AUTOSAR XML (schema 4-2-1)
package /RootP_ASWC_M137
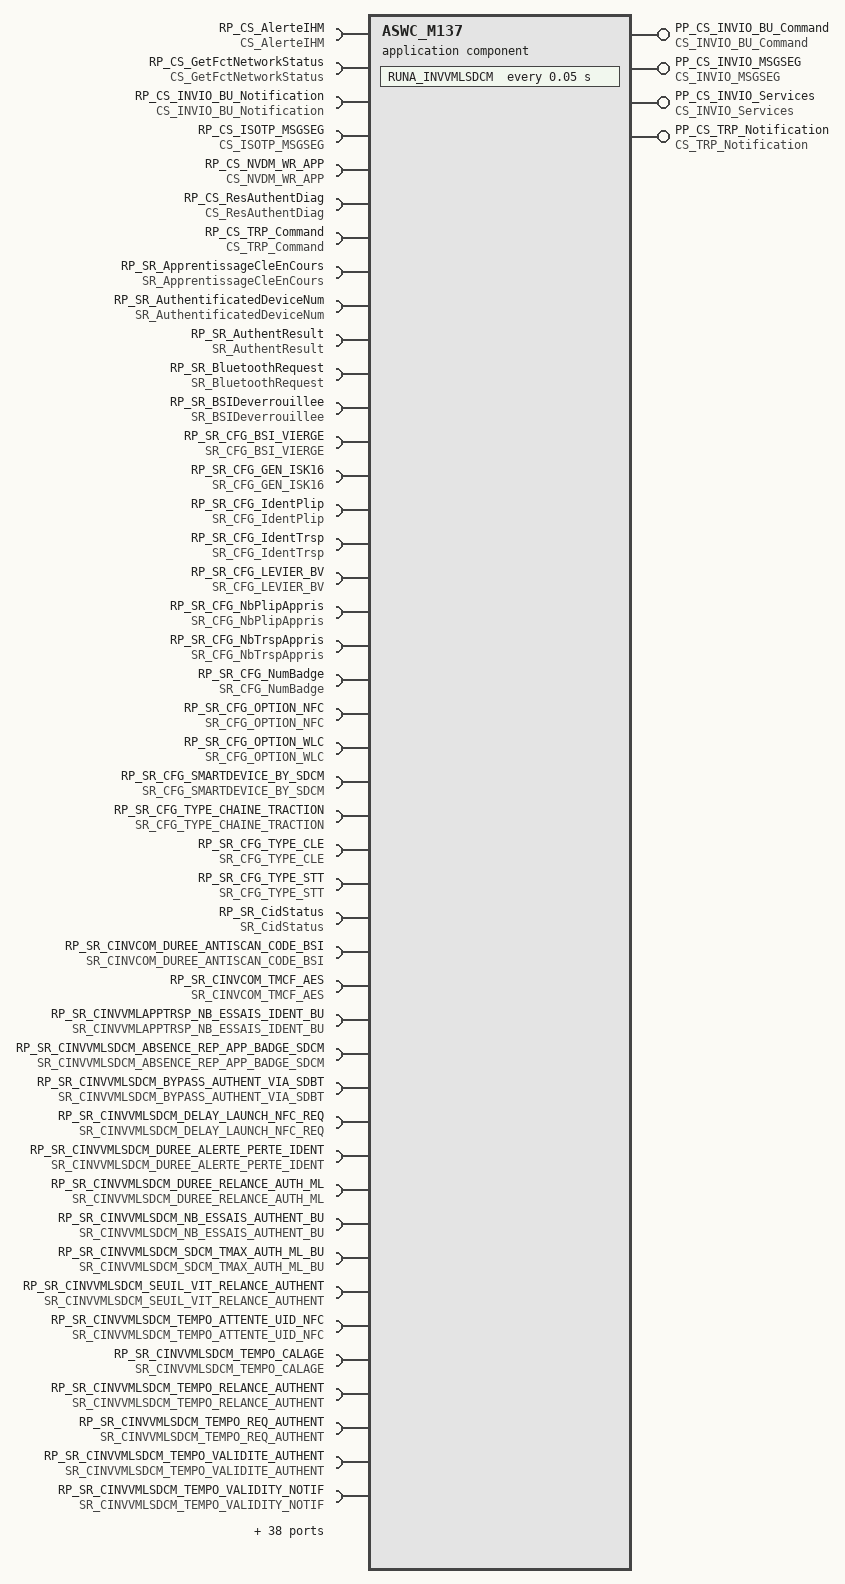
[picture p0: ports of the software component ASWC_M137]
  application sw component type ASWC_M137
    4 x provide port:
      PP_CS_INVIO_BU_Command: provided-interface=CS_INVIO_BU_Command
        provided-com-specs:
          operation=Invio_AuthentRequest, queue-length=1
          operation=Invio_CfgReadRequest, queue-length=1
          operation=Invio_CfgWriteRequest, queue-length=1
          operation=Invio_IdentRequest, queue-length=1
          operation=Invio_ReadRequest, queue-length=1
          operation=Invio_WriteRequest, queue-length=1
      PP_CS_INVIO_MSGSEG: server-com-spec{operation=Invio_ReceiveSegMsg, queue-length=1}, provided-interface=CS_INVIO_MSGSEG
      PP_CS_INVIO_Services: provided-interface=CS_INVIO_Services
        provided-com-specs:
          operation=Invio_CalculerDataAuthent, queue-length=1
          operation=Invio_CalculerRSK, queue-length=1
          operation=Invio_FinAppr, queue-length=1
          operation=Invio_GetCIDAndStatus, queue-length=1
          operation=Invio_LocalisationMLEnCours, queue-length=1
      PP_CS_TRP_Notification: provided-interface=CS_TRP_Notification
        provided-com-specs:
          operation=Authent_Result, queue-length=1
          operation=Cfg_Read_Result, queue-length=1
          operation=Cfg_Write_Result, queue-length=1
          operation=Error, queue-length=1
          operation=Ident_Result, queue-length=1
          operation=Read_Result, queue-length=1
          operation=Write_Result, queue-length=1
    33 x provide/require port:
      PRP_SR_AnimationPushDem: provided-required-interface=SR_AnimationPushDem
        required-com-specs:
          data-element=DmdPoumonagePushDem, enable-update=0, handle-data-status=1, handle-never-received=0, init-value=CONST_DmdPoumonagePushDem_t_cDmdPoumonagePushDem_cDmdPoumonagePushDem_Aucun:0
          data-element=DmdRetroPushDem, enable-update=0, handle-data-status=1, handle-never-received=0, init-value=CONST_DmdRetroPushDem_t_cPushDem_cPushDem_Eteint:0
      PRP_SR_AppuiPushTraite: nonqueued-receiver-com-spec{data-element=AppuiPushTraite, enable-update=0, handle-data-status=1, handle-never-received=0, init-value=CONST_tLOG_0:0}, provided-required-interface=SR_AppuiPushTraite
      PRP_SR_AuthentBUDemandee: nonqueued-receiver-com-spec{data-element=AuthentBUDemandee, enable-update=0, handle-data-status=1, handle-never-received=0, init-value=CONST_tLOG_0:0}, provided-required-interface=SR_AuthentBUDemandee
      PRP_SR_AuthentificationBU: nonqueued-receiver-com-spec{data-element=AuthentificationBU, enable-update=0, handle-data-status=1, handle-never-received=0, init-value=CONST_tLOG_0:0}, provided-required-interface=SR_AuthentificationBU
      PRP_SR_AuthentificationBUMux: nonqueued-receiver-com-spec{data-element=AuthentificationBUMux, enable-update=0, handle-data-status=1, handle-never-received=0, init-value=CONST_tLOG_0:0}, provided-required-interface=SR_AuthentificationBUMux
      PRP_SR_AuthentificationML: nonqueued-receiver-com-spec{data-element=AuthentificationML, enable-update=0, handle-data-status=1, handle-never-received=0, init-value=CONST_tLOG_0:0}, provided-required-interface=SR_AuthentificationML
      PRP_SR_AuthentificationMLnonSDF: nonqueued-receiver-com-spec{data-element=AuthentificationMLnonSDF, enable-update=0, handle-data-status=1, handle-never-received=0, init-value=CONST_tLOG_0:0}, provided-required-interface=SR_AuthentificationMLnonSDF
      PRP_SR_AuthentMLDemandee: nonqueued-receiver-com-spec{data-element=AuthentMLDemandee, enable-update=0, handle-data-status=1, handle-never-received=0, init-value=CONST_tLOG_0:0}, provided-required-interface=SR_AuthentMLDemandee
      PRP_SR_DmdAffIHMAuthent: nonqueued-receiver-com-spec{data-element=DmdAffIHMAuthent, enable-update=0, handle-data-status=1, handle-never-received=0, init-value=CONST_tLOG_0:0}, provided-required-interface=SR_DmdAffIHMAuthent
      PRP_SR_DmdAuthentBU: nonqueued-receiver-com-spec{data-element=DmdAuthentBU, enable-update=0, handle-data-status=1, handle-never-received=0, init-value=CONST_tQUARTET_0:0}, provided-required-interface=SR_DmdAuthentBU
      PRP_SR_DmdIdentBU: nonqueued-receiver-com-spec{data-element=DmdIdentBU, enable-update=0, handle-data-status=1, handle-never-received=0, init-value=CONST_tQUARTET_0:0}, provided-required-interface=SR_DmdIdentBU
      PRP_SR_EtatLocalisationML: nonqueued-receiver-com-spec{data-element=EtatLocalisationML, enable-update=0, handle-data-status=1, handle-never-received=0, init-value=CONST_EtatLocalisationML_t_Localis_cNonLocalise:0}, provided-required-interface=SR_EtatLocalisationML
      PRP_SR_HfResultatAuthentML: nonqueued-receiver-com-spec{data-element=ToggleAuthentML, enable-update=0, handle-data-status=1, handle-never-received=0, init-value=CONST_tLOG_0:0}, provided-required-interface=SR_HfResultatAuthentML
      PRP_SR_IdentBUDemandee: nonqueued-receiver-com-spec{data-element=IdentBUDemandee, enable-update=0, handle-data-status=1, handle-never-received=0, init-value=CONST_tLOG_0:0}, provided-required-interface=SR_IdentBUDemandee
      PRP_SR_IdentTrspBU: nonqueued-receiver-com-spec{data-element=IdentTrspBU, enable-update=0, handle-data-status=1, handle-never-received=0, init-value=CONST_tDWORD_0:0}, provided-required-interface=SR_IdentTrspBU
      PRP_SR_LastIdUsedToStart: provided-required-interface=SR_LastIdUsedToStart
        required-com-specs:
          data-element=LastNumIdUsedToStart, enable-update=0, handle-data-status=1, handle-never-received=0, init-value=CONST_tBYTE_0:0
          data-element=LastTypeIdUsedToStart, enable-update=0, handle-data-status=1, handle-never-received=0, init-value=CONST_t_cLastTypeId_0:0
      PRP_SR_NbNFCUidAppris: nonqueued-receiver-com-spec{data-element=NbNFCUidAppris, enable-update=0, handle-data-status=1, handle-never-received=0, init-value=CONST_tBYTE_0:0}, provided-required-interface=SR_NbNFCUidAppris
      PRP_SR_NFCUidLearningEcuState: nonqueued-receiver-com-spec{data-element=NFCUidLearningEcuState, enable-update=0, handle-data-status=1, handle-never-received=0, init-value=CONST_tLOG_0:0}, provided-required-interface=SR_NFCUidLearningEcuState
      PRP_SR_NoIMLAuthentOnStartRequest: nonqueued-receiver-com-spec{data-element=NoIMLAuthentOnStartRequest, enable-update=0, handle-data-status=1, handle-never-received=0, init-value=CONST_tLOG_0:0}, provided-required-interface=SR_NoIMLAuthentOnStartRequest
      PRP_SR_PresenceClefAppriseBU: nonqueued-receiver-com-spec{data-element=PresenceClefAppriseBU, enable-update=0, handle-data-status=1, handle-never-received=0, init-value=CONST_tLOG_0:0}, provided-required-interface=SR_PresenceClefAppriseBU
      PRP_SR_ReqAuthentBTSD: nonqueued-receiver-com-spec{data-element=ReqAuthentBTSD, enable-update=0, handle-data-status=1, handle-never-received=0, init-value=CONST_t_cReqAuthent_0:0}, provided-required-interface=SR_ReqAuthentBTSD
      PRP_SR_ReqAuthentCID: nonqueued-receiver-com-spec{data-element=ReqAuthentCID, enable-update=0, handle-data-status=1, handle-never-received=0, init-value=CONST_t_cReqAuthent_0:0}, provided-required-interface=SR_ReqAuthentCID
      PRP_SR_ReqAuthentNFCCard: nonqueued-receiver-com-spec{data-element=ReqAuthentNFCCard, enable-update=0, handle-data-status=1, handle-never-received=0, init-value=CONST_t_cReqAuthent_0:0}, provided-required-interface=SR_ReqAuthentNFCCard
      PRP_SR_ReqAuthentNFCSD: nonqueued-receiver-com-spec{data-element=ReqAuthentNFCSD, enable-update=0, handle-data-status=1, handle-never-received=0, init-value=CONST_t_cReqAuthent_0:0}, provided-required-interface=SR_ReqAuthentNFCSD
      PRP_SR_ReqLearnUIDTableBSI: nonqueued-receiver-com-spec{data-element=ReqLearnUIDTableToBSI, enable-update=0, handle-data-status=1, handle-never-received=0, init-value=CONST_tLOG_0:0}, provided-required-interface=SR_ReqLearnUIDTableBSI
      PRP_SR_SDCMBlacklistingRq: nonqueued-receiver-com-spec{data-element=SDCMBlacklistingRq, enable-update=0, handle-data-status=1, handle-never-received=0, init-value=CONST_tLOG_0:0}, provided-required-interface=SR_SDCMBlacklistingRq
      PRP_SR_SDCMProg: provided-required-interface=SR_SDCMProg
        required-com-specs:
          data-element=SDCMCodeNumber, enable-update=0, handle-data-status=1, handle-never-received=0, init-value=CONST_tBYTE_0:0
          data-element=SDCMPackageCounter, enable-update=0, handle-data-status=1, handle-never-received=0, init-value=CONST_tBYTE_0:0
          data-element=SDCMProgCodelb, enable-update=0, handle-data-status=1, handle-never-received=0, init-value=CONST_tDWORD_0:0
          data-element=SDCMProgCodemb, enable-update=0, handle-data-status=1, handle-never-received=0, init-value=CONST_tDWORD_0:0
      PRP_SR_SDCMUnblacklistingRq: nonqueued-receiver-com-spec{data-element=SDCMUnblacklistingRq, enable-update=0, handle-data-status=1, handle-never-received=0, init-value=CONST_tLOG_0:0}, provided-required-interface=SR_SDCMUnblacklistingRq
      PRP_SR_SmartDeviceActivation: nonqueued-receiver-com-spec{data-element=SmartDeviceActivation, enable-update=0, handle-data-status=1, handle-never-received=0, init-value=CONST_tLOG_1:1}, provided-required-interface=SR_SmartDeviceActivation
      PRP_SR_StatutApprNFCUid: nonqueued-receiver-com-spec{data-element=StatutApprNFCUid, enable-update=0, handle-data-status=1, handle-never-received=0, init-value=CONST_t_cApprNFCUid_0:0}, provided-required-interface=SR_StatutApprNFCUid
      PRP_SR_ToggleAuthentBU: nonqueued-receiver-com-spec{data-element=ToggleAuthentBU, enable-update=0, handle-data-status=1, handle-never-received=0, init-value=CONST_tLOG_0:0}, provided-required-interface=SR_ToggleAuthentBU
      PRP_SR_ToggleErrorBU: nonqueued-receiver-com-spec{data-element=ToggleErrorBU, enable-update=0, handle-data-status=1, handle-never-received=0, init-value=CONST_tLOG_0:0}, provided-required-interface=SR_ToggleErrorBU
      PRP_SR_ToggleIdentBU: nonqueued-receiver-com-spec{data-element=ToggleIdentBU, enable-update=0, handle-data-status=1, handle-never-received=0, init-value=CONST_tLOG_0:0}, provided-required-interface=SR_ToggleIdentBU
    84 x require port:
      RP_CS_AlerteIHM: required-interface=CS_AlerteIHM
      RP_CS_GetFctNetworkStatus: required-interface=CS_GetFctNetworkStatus
      RP_CS_INVIO_BU_Notification: required-interface=CS_INVIO_BU_Notification
      RP_CS_ISOTP_MSGSEG: required-interface=CS_ISOTP_MSGSEG
      RP_CS_NVDM_WR_APP: required-interface=CS_NVDM_WR_APP
      RP_CS_ResAuthentDiag: required-interface=CS_ResAuthentDiag
      RP_CS_TRP_Command: required-interface=CS_TRP_Command
      RP_SR_ApprentissageCleEnCours: nonqueued-receiver-com-spec{data-element=ApprentissageCleEnCours, enable-update=0, handle-data-status=1, handle-never-received=0, init-value=CONST_tLOG_0:0}, required-interface=SR_ApprentissageCleEnCours
      RP_SR_AuthentificatedDeviceNum: nonqueued-receiver-com-spec{data-element=AuthentificatedDeviceNum, enable-update=0, handle-data-status=1, handle-never-received=0, init-value=CONST_tBYTE_0:0}, required-interface=SR_AuthentificatedDeviceNum
      RP_SR_AuthentResult: required-interface=SR_AuthentResult
        required-com-specs:
          data-element=ResAuthentBTSD, enable-update=0, handle-data-status=1, handle-never-received=0, init-value=CONST_ResAuthentBTSD_t_cResAuthent_cResAuthent_Pending:1
          data-element=ResAuthentCID, enable-update=0, handle-data-status=1, handle-never-received=0, init-value=CONST_ResAuthentCID_t_cResAuthent_cResAuthent_Pending:1
          data-element=ResAuthentNFCCard, enable-update=0, handle-data-status=1, handle-never-received=0, init-value=CONST_ResAuthentNFCCard_t_cResAuthent_cResAuthent_Pending:1
          data-element=ResAuthentNFCSD, enable-update=0, handle-data-status=1, handle-never-received=0, init-value=CONST_ResAuthentNFCSD_t_cResAuthent_cResAuthent_Pending:1
      RP_SR_BluetoothRequest: nonqueued-receiver-com-spec{data-element=RqBTStartingAutorization, enable-update=0, handle-data-status=1, handle-never-received=0, init-value=CONST_tLOG_0:0}, required-interface=SR_BluetoothRequest
      RP_SR_BSIDeverrouillee: nonqueued-receiver-com-spec{data-element=BSIDeverrouillee, enable-update=0, handle-data-status=1, handle-never-received=0, init-value=CONST_tLOG_0:0}, required-interface=SR_BSIDeverrouillee
      RP_SR_CFG_BSI_VIERGE: nonqueued-receiver-com-spec{data-element=CFG_BSI_VIERGE, enable-update=0, handle-data-status=1, handle-never-received=0, init-value=CONST_tLOG_1:1}, required-interface=SR_CFG_BSI_VIERGE
      RP_SR_CFG_GEN_ISK16: nonqueued-receiver-com-spec{data-element=CFG_GEN_ISK16, enable-update=0, handle-data-status=1, handle-never-received=0, init-value=CONST_tLOG_1:1}, required-interface=SR_CFG_GEN_ISK16
      RP_SR_CFG_IdentPlip: required-interface=SR_CFG_IdentPlip
        required-com-specs:
          data-element=CFG_IdentPlip{1..5}, enable-update=0, handle-data-status=1, handle-never-received=0, init-value=CONST_tDWORD_0:0
      RP_SR_CFG_IdentTrsp: required-interface=SR_CFG_IdentTrsp
        required-com-specs:
          data-element=CFG_IdentTrsp{1..5}, enable-update=0, handle-data-status=1, handle-never-received=0, init-value=CONST_tDWORD_0:0
      RP_SR_CFG_LEVIER_BV: nonqueued-receiver-com-spec{data-element=CFG_LEVIER_BV, enable-update=0, handle-data-status=1, handle-never-received=0, init-value=CONST_t_cLevierBV_3:3}, required-interface=SR_CFG_LEVIER_BV
      RP_SR_CFG_NbPlipAppris: nonqueued-receiver-com-spec{data-element=CFG_NbPlipAppris, enable-update=0, handle-data-status=1, handle-never-received=0, init-value=CONST_tBYTE_0:0}, required-interface=SR_CFG_NbPlipAppris
      RP_SR_CFG_NbTrspAppris: nonqueued-receiver-com-spec{data-element=CFG_NbTrspAppris, enable-update=0, handle-data-status=1, handle-never-received=0, init-value=CONST_tBYTE_0:0}, required-interface=SR_CFG_NbTrspAppris
      RP_SR_CFG_NumBadge: required-interface=SR_CFG_NumBadge
        required-com-specs:
          data-element=CFG_NumBadge{1..5}, enable-update=0, handle-data-status=1, handle-never-received=0, init-value=CONST_t_CFG_NumBadge_0:0
      RP_SR_CFG_OPTION_NFC: nonqueued-receiver-com-spec{data-element=CFG_OPTION_NFC, enable-update=0, handle-data-status=1, handle-never-received=0, init-value=CONST_CFG_OPTION_NFC_t_CFG_OPTION_NFC_cOptNFC_Without:0}, required-interface=SR_CFG_OPTION_NFC
      RP_SR_CFG_OPTION_WLC: nonqueued-receiver-com-spec{data-element=CFG_OPTION_WLC, enable-update=0, handle-data-status=1, handle-never-received=0, init-value=CONST_tLOG_0:0}, required-interface=SR_CFG_OPTION_WLC
      RP_SR_CFG_SMARTDEVICE_BY_SDCM: nonqueued-receiver-com-spec{data-element=CFG_SMARTDEVICE_BY_SDCM, enable-update=0, handle-data-status=1, handle-never-received=0, init-value=CONST_t_cSDBySDCM_With_1:1}, required-interface=SR_CFG_SMARTDEVICE_BY_SDCM
      RP_SR_CFG_TYPE_CHAINE_TRACTION: nonqueued-receiver-com-spec{data-element=CFG_TYPE_CHAINE_TRACTION, enable-update=0, handle-data-status=1, handle-never-received=0, init-value=CONST_CFG_TYPE_CHAINE_TRACTION_t_cTCT_cTCT_MTH:0}, required-interface=SR_CFG_TYPE_CHAINE_TRACTION
      RP_SR_CFG_TYPE_CLE: nonqueued-receiver-com-spec{data-element=CFG_TYPE_CLE, enable-update=0, handle-data-status=1, handle-never-received=0, init-value=CONST_t_cTypeCle_Cle_2:2}, required-interface=SR_CFG_TYPE_CLE
      RP_SR_CFG_TYPE_STT: nonqueued-receiver-com-spec{data-element=CFG_TYPE_STT, enable-update=0, handle-data-status=1, handle-never-received=0, init-value=CONST_CFG_TYPE_STT_t_cSTT_cSTT_Absent:0}, required-interface=SR_CFG_TYPE_STT
      RP_SR_CidStatus: required-interface=SR_CidStatus
        required-com-specs:
          data-element=Cid{1..5}Status, enable-update=0, handle-data-status=1, handle-never-received=0, init-value=CONST_tLOG_0:0
      RP_SR_CINVCOM_DUREE_ANTISCAN_CODE_BSI: nonqueued-receiver-com-spec{data-element=CINVCOM_DUREE_ANTISCAN_CODE_BSI, enable-update=0, handle-data-status=1, handle-never-received=0, init-value=CONST_tWORD_900:900}, required-interface=SR_CINVCOM_DUREE_ANTISCAN_CODE_BSI
      RP_SR_CINVCOM_TMCF_AES: nonqueued-receiver-com-spec{data-element=CINVCOM_TMCF_AES, enable-update=0, handle-data-status=1, handle-never-received=0, init-value=CONST_tBYTE_0:0}, required-interface=SR_CINVCOM_TMCF_AES
      RP_SR_CINVVMLAPPTRSP_NB_ESSAIS_IDENT_BU: nonqueued-receiver-com-spec{data-element=CINVVMLAPPTRSP_NB_ESSAIS_IDENT_BU, enable-update=0, handle-data-status=1, handle-never-received=0, init-value=CONST_t_INVIO_NB_ESSAIS_IDENT_BU_7:7}, required-interface=SR_CINVVMLAPPTRSP_NB_ESSAIS_IDENT_BU
      RP_SR_CINVVMLSDCM_ABSENCE_REP_APP_BADGE_SDCM: nonqueued-receiver-com-spec{data-element=CINVVMLSDCM_ABSENCE_REP_APP_BADGE_SDCM, enable-update=0, handle-data-status=1, handle-never-received=0, init-value=CONST_tBYTE_12:12}, required-interface=SR_CINVVMLSDCM_ABSENCE_REP_APP_BADGE_SDCM
      RP_SR_CINVVMLSDCM_BYPASS_AUTHENT_VIA_SDBT: nonqueued-receiver-com-spec{data-element=CINVVMLSDCM_BYPASS_AUTHENT_VIA_SDBT, enable-update=0, handle-data-status=1, handle-never-received=0, init-value=CONST_tLOG_1:1}, required-interface=SR_CINVVMLSDCM_BYPASS_AUTHENT_VIA_SDBT
      RP_SR_CINVVMLSDCM_DELAY_LAUNCH_NFC_REQ: nonqueued-receiver-com-spec{data-element=CINVVMLSDCM_DELAY_LAUNCH_NFC_REQ, enable-update=0, handle-data-status=1, handle-never-received=0, init-value=CONST_t_INVIO_SDCM_DELAY_LAUNCH_NFC_REQ_2:2}, required-interface=SR_CINVVMLSDCM_DELAY_LAUNCH_NFC_REQ
      RP_SR_CINVVMLSDCM_DUREE_ALERTE_PERTE_IDENT: nonqueued-receiver-com-spec{data-element=CINVVMLSDCM_DUREE_ALERTE_PERTE_IDENT, enable-update=0, handle-data-status=1, handle-never-received=0, init-value=CONST_t_INVIO_DUREE_ALERTE_PERTE_IDENT_10:10}, required-interface=SR_CINVVMLSDCM_DUREE_ALERTE_PERTE_IDENT
      RP_SR_CINVVMLSDCM_DUREE_RELANCE_AUTH_ML: nonqueued-receiver-com-spec{data-element=CINVVMLSDCM_DUREE_RELANCE_AUTH_ML, enable-update=0, handle-data-status=1, handle-never-received=0, init-value=CONST_t_INVIO_DUREE_RELANCE_AUTH_ML_3:3}, required-interface=SR_CINVVMLSDCM_DUREE_RELANCE_AUTH_ML
      RP_SR_CINVVMLSDCM_NB_ESSAIS_AUTHENT_BU: nonqueued-receiver-com-spec{data-element=CINVVMLSDCM_NB_ESSAIS_AUTHENT_BU, enable-update=0, handle-data-status=1, handle-never-received=0, init-value=CONST_t_INVIO_NB_ESSAIS_AUTHENT_BU_7:7}, required-interface=SR_CINVVMLSDCM_NB_ESSAIS_AUTHENT_BU
      RP_SR_CINVVMLSDCM_SDCM_TMAX_AUTH_ML_BU: nonqueued-receiver-com-spec{data-element=CINVVMLSDCM_SDCM_TMAX_AUTH_ML_BU, enable-update=0, handle-data-status=1, handle-never-received=0, init-value=CONST_t_INVIO_SDCM_TMAX_AUTH_ML_BU_100:100}, required-interface=SR_CINVVMLSDCM_SDCM_TMAX_AUTH_ML_BU
      RP_SR_CINVVMLSDCM_SEUIL_VIT_RELANCE_AUTHENT: nonqueued-receiver-com-spec{data-element=CINVVMLSDCM_SEUIL_VIT_RELANCE_AUTHENT, enable-update=0, handle-data-status=1, handle-never-received=0, init-value=CONST_t_INVIO_SEUIL_VIT_RELANCE_AUTHENT_20:20}, required-interface=SR_CINVVMLSDCM_SEUIL_VIT_RELANCE_AUTHENT
      RP_SR_CINVVMLSDCM_TEMPO_ATTENTE_UID_NFC: nonqueued-receiver-com-spec{data-element=CINVVMLSDCM_TEMPO_ATTENTE_UID_NFC, enable-update=0, handle-data-status=1, handle-never-received=0, init-value=CONST_t_INVIO_TEMPO_ATTENTE_UID_NFC_5:5}, required-interface=SR_CINVVMLSDCM_TEMPO_ATTENTE_UID_NFC
      RP_SR_CINVVMLSDCM_TEMPO_CALAGE: nonqueued-receiver-com-spec{data-element=CINVVMLSDCM_TEMPO_CALAGE, enable-update=0, handle-data-status=1, handle-never-received=0, init-value=CONST_tBYTE_6:6}, required-interface=SR_CINVVMLSDCM_TEMPO_CALAGE
      RP_SR_CINVVMLSDCM_TEMPO_RELANCE_AUTHENT: nonqueued-receiver-com-spec{data-element=CINVVMLSDCM_TEMPO_RELANCE_AUTHENT, enable-update=0, handle-data-status=1, handle-never-received=0, init-value=CONST_t_INVIO_SDCM_TEMPO_RELANCE_AUTHENT_30:30}, required-interface=SR_CINVVMLSDCM_TEMPO_RELANCE_AUTHENT
      RP_SR_CINVVMLSDCM_TEMPO_REQ_AUTHENT: nonqueued-receiver-com-spec{data-element=CINVVMLSDCM_TEMPO_REQ_AUTHENT, enable-update=0, handle-data-status=1, handle-never-received=0, init-value=CONST_t_INVIO_SDCM_TEMPO_REQ_AUTHENT_10:10}, required-interface=SR_CINVVMLSDCM_TEMPO_REQ_AUTHENT
      RP_SR_CINVVMLSDCM_TEMPO_VALIDITE_AUTHENT: nonqueued-receiver-com-spec{data-element=CINVVMLSDCM_TEMPO_VALIDITE_AUTHENT, enable-update=0, handle-data-status=1, handle-never-received=0, init-value=CONST_tBYTE_10:10}, required-interface=SR_CINVVMLSDCM_TEMPO_VALIDITE_AUTHENT
      RP_SR_CINVVMLSDCM_TEMPO_VALIDITY_NOTIF: nonqueued-receiver-com-spec{data-element=CINVVMLSDCM_TEMPO_VALIDITY_NOTIF, enable-update=0, handle-data-status=1, handle-never-received=0, init-value=CONST_t_INVIO_SDCM_TEMPO_VALIDITY_NOTIF_10:10}, required-interface=SR_CINVVMLSDCM_TEMPO_VALIDITY_NOTIF
      RP_SR_CINVVMLSDCM_TIMEOUT_POLLING_AUTHENT_ML: nonqueued-receiver-com-spec{data-element=CINVVMLSDCM_TIMEOUT_POLLING_AUTHENT_ML, enable-update=0, handle-data-status=1, handle-never-received=0, init-value=CONST_t_INVIO_TIMEOUT_POLLING_AUTHENT_ML_1:1}, required-interface=SR_CINVVMLSDCM_TIMEOUT_POLLING_AUTHENT_ML
      RP_SR_CINVVMLSDCM_TMAX_AUTH_CID: nonqueued-receiver-com-spec{data-element=CINVVMLSDCM_TMAX_AUTH_CID, enable-update=0, handle-data-status=1, handle-never-received=0, init-value=CONST_t_INVIO_SDCM_TMAX_AUTH_CID_70:70}, required-interface=SR_CINVVMLSDCM_TMAX_AUTH_CID
      RP_SR_CINVVMLSDCM_TMAX_AUTH_NFC_CARD: nonqueued-receiver-com-spec{data-element=CINVVMLSDCM_TMAX_AUTH_NFC_CARD, enable-update=0, handle-data-status=1, handle-never-received=0, init-value=CONST_t_INVIO_SDCM_TMAX_AUTH_NFC_CARD_70:70}, required-interface=SR_CINVVMLSDCM_TMAX_AUTH_NFC_CARD
      RP_SR_CINVVMLSDCM_TMAX_AUTH_SD_BT: nonqueued-receiver-com-spec{data-element=CINVVMLSDCM_TMAX_AUTH_SD_BT, enable-update=0, handle-data-status=1, handle-never-received=0, init-value=CONST_t_INVIO_SDCM_TMAX_AUTH_SD_BT_70:70}, required-interface=SR_CINVVMLSDCM_TMAX_AUTH_SD_BT
      RP_SR_CINVVMLSDCM_WASH_MODE_ACTIV_AUTHENT: nonqueued-receiver-com-spec{data-element=CINVVMLSDCM_WASH_MODE_ACTIV_AUTHENT, enable-update=0, handle-data-status=1, handle-never-received=0, init-value=CONST_tLOG_1:1}, required-interface=SR_CINVVMLSDCM_WASH_MODE_ACTIV_AUTHENT
      RP_SR_CINVVMLSDCM_WASH_MODE_NB_RETRY: nonqueued-receiver-com-spec{data-element=CINVVMLSDCM_WASH_MODE_NB_RETRY, enable-update=0, handle-data-status=1, handle-never-received=0, init-value=CONST_t_INVIO_WASH_MODE_NB_RETRY_1:1}, required-interface=SR_CINVVMLSDCM_WASH_MODE_NB_RETRY
      RP_SR_CINVVMLSDCM_WASH_MODE_POLLING_TIMEOUT: nonqueued-receiver-com-spec{data-element=CINVVMLSDCM_WASH_MODE_POLLING_TIMEOUT, enable-update=0, handle-data-status=1, handle-never-received=0, init-value=CONST_t_INVIO_WASH_MODE_POLLING_TIMEOUT_70:70}, required-interface=SR_CINVVMLSDCM_WASH_MODE_POLLING_TIMEOUT
      RP_SR_CodeADC: required-interface=SR_CodeADC
        required-com-specs:
          data-element=CodeADC{1..4}, enable-update=0, handle-data-status=1, handle-never-received=0, init-value=CONST_tDWORD_0:0
      RP_SR_CodeVIN_{15..17}: nonqueued-receiver-com-spec{data-element=CodeVIN_{15..17}, enable-update=0, handle-data-status=1, handle-never-received=0, init-value=CONST_tBYTE_0xFE:254}, required-interface=SR_CodeVIN_{15..17}
      RP_SR_ConducteurAuthDsHAB: nonqueued-receiver-com-spec{data-element=ConducteurAuthDsHAB, enable-update=0, handle-data-status=1, handle-never-received=0, init-value=CONST_tLOG_0:0}, required-interface=SR_ConducteurAuthDsHAB
      RP_SR_DisplaySdStartingAutorIcon: nonqueued-receiver-com-spec{data-element=DisplaySdStartingAutorIcon, enable-update=0, handle-data-status=1, handle-never-received=0, init-value=CONST_tBYTE_0:0}, required-interface=SR_DisplaySdStartingAutorIcon
      RP_SR_DmdAppuiPush: nonqueued-receiver-com-spec{data-element=DmdAppuiPush, enable-update=0, handle-data-status=1, handle-never-received=0, init-value=CONST_tLOG_0:0}, required-interface=SR_DmdAppuiPush
      RP_SR_DmdAuthentTrspDiag: nonqueued-receiver-com-spec{data-element=DmdAuthentTrspDiag, enable-update=0, handle-data-status=1, handle-never-received=0, init-value=CONST_tLOG_0:0}, required-interface=SR_DmdAuthentTrspDiag
      RP_SR_DysfVitesseVehicule: nonqueued-receiver-com-spec{data-element=DysfVitesseVehicule, enable-update=0, handle-data-status=1, handle-never-received=0, init-value=CONST_t_cVitv_0:0}, required-interface=SR_DysfVitesseVehicule
      RP_SR_EtatGMP: nonqueued-receiver-com-spec{data-element=EtatGMP, enable-update=0, handle-data-status=1, handle-never-received=0, init-value=CONST_EtatGMP_t_GM_GMP_GM_GMPCoupe:1}, required-interface=SR_EtatGMP
      RP_SR_EtatMenuINV_ADSD: nonqueued-receiver-com-spec{data-element=EtatMenuINV_ADSD, enable-update=0, handle-data-status=1, handle-never-received=0, init-value=CONST_tLOG_0:0}, required-interface=SR_EtatMenuINV_ADSD
      RP_SR_EtatPrincipalSEV: nonqueued-receiver-com-spec{data-element=EtatPrincipalSEV, enable-update=0, handle-data-status=1, handle-never-received=0, init-value=CONST_EtatPrincipalSEV_t_SEV_SEV_Arret:105}, required-interface=SR_EtatPrincipalSEV
      RP_SR_HfResultatLocIDMLIntFull: required-interface=SR_HfResultatLocIDMLIntFull
        required-com-specs:
          data-element=LocIDMLIntFull, enable-update=0, handle-data-status=1, handle-never-received=0, init-value=CONST_tBYTE_0:0
          data-element=ToggleLocIDMLIntFull, enable-update=0, handle-data-status=1, handle-never-received=0, init-value=CONST_tLOG_0:0
      RP_SR_InterMemoDefauts: nonqueued-receiver-com-spec{data-element=InterMemoDefauts, enable-update=0, handle-data-status=1, handle-never-received=0, init-value=CONST_tLOG_0:0}, required-interface=SR_InterMemoDefauts
      RP_SR_LncDdeAuthentML: nonqueued-receiver-com-spec{data-element=LncDdeAuthentML, enable-update=0, handle-data-status=1, handle-never-received=0, init-value=CONST_tLOG_0:0}, required-interface=SR_LncDdeAuthentML
      RP_SR_LocalisationStatus: required-interface=SR_LocalisationStatus
        required-com-specs:
          data-element=ExternalLocalisationStatus, enable-update=0, handle-data-status=1, handle-never-received=0, init-value=CONST_ExternalLocalisationStatus_t_LocalisationStatus_eLocStatus_NotRunning:0
          data-element=InternalLocalisationStatus, enable-update=0, handle-data-status=1, handle-never-received=0, init-value=CONST_InternalLocalisationStatus_t_LocalisationStatus_eLocStatus_NotRunning:0
      RP_SR_NotifyRxSdcm: nonqueued-receiver-com-spec{data-element=NotifyRxSdcm, enable-update=0, handle-data-status=1, handle-never-received=0, init-value=CONST_tBYTE_0:0}, required-interface=SR_NotifyRxSdcm
      RP_SR_PhaseVieLS: nonqueued-receiver-com-spec{data-element=PhaseVieLS, enable-update=0, handle-data-status=1, handle-never-received=0, init-value=CONST_t_cCANLS_0:0}, required-interface=SR_PhaseVieLS
      RP_SR_ReqLearnUIDTableToSDCM: nonqueued-receiver-com-spec{data-element=ReqLearnUIDTableToSDCM, enable-update=0, handle-data-status=1, handle-never-received=0, init-value=CONST_tLOG_0:0}, required-interface=SR_ReqLearnUIDTableToSDCM
      RP_SR_SAV_CondaRealisee: nonqueued-receiver-com-spec{data-element=SAV_CondaRealisee, enable-update=0, handle-data-status=1, handle-never-received=0, init-value=CONST_SAV_CondaRealisee_t_cCR_cCR_Decondamne:1}, required-interface=SR_SAV_CondaRealisee
      RP_SR_SAV_EtatOuvrants: nonqueued-receiver-com-spec{data-element=SAV_EtatOuvrants, enable-update=0, handle-data-status=1, handle-never-received=0, init-value=CONST_t_cmEO_0:0}, required-interface=SR_SAV_EtatOuvrants
      RP_SR_SdcmAuthorisation: nonqueued-receiver-com-spec{data-element=SdcmAuthorisation, enable-update=0, handle-data-status=1, handle-never-received=0, init-value=CONST_tLOG_1:1}, required-interface=SR_SdcmAuthorisation
      RP_SR_SDCMBlacklistingTask: nonqueued-receiver-com-spec{data-element=SDCMBlacklistingTask, enable-update=0, handle-data-status=1, handle-never-received=0, init-value=CONST_t_Blacklist_0:0}, required-interface=SR_SDCMBlacklistingTask
      RP_SR_SDCMCodeAppairRes: nonqueued-receiver-com-spec{data-element=SDCMCodeAppairRes, enable-update=0, handle-data-status=1, handle-never-received=0, init-value=CONST_t_cSDCMCodeAppair_0:0}, required-interface=SR_SDCMCodeAppairRes
      RP_SR_SEC_ConfigSEV: nonqueued-receiver-com-spec{data-element=SEC_ConfigSEV, enable-update=0, handle-data-status=1, handle-never-received=0, init-value=CONST_t_cCSEV_4:4}, required-interface=SR_SEC_ConfigSEV
      RP_SR_SecuApprData: required-interface=SR_SecuApprData
        required-com-specs:
          data-element=DmdSecuKeyLearning, enable-update=0, handle-data-status=1, handle-never-received=0, init-value=CONST_DmdSecuKeyLearning_t_cSecuKey_cSecuKey_None:0
          data-element=KeyLearningValidFlag, enable-update=0, handle-data-status=1, handle-never-received=0, init-value=CONST_tLOG_0:0
      RP_SR_SessionDiagEncours: nonqueued-receiver-com-spec{data-element=SessionDiagEncours, enable-update=0, handle-data-status=1, handle-never-received=0, init-value=CONST_tLOG_0:1}, required-interface=SR_SessionDiagEncours
      RP_SR_SEVDem: nonqueued-receiver-com-spec{data-element=SEVDem, enable-update=0, handle-data-status=1, handle-never-received=0, init-value=CONST_SEVDem_t_cVolonteDem_cVolonteDem_Absente:1}, required-interface=SR_SEVDem
      RP_SR_ToggleReqAuthentForLoc: nonqueued-receiver-com-spec{data-element=ToggleReqAuthentForLoc, enable-update=0, handle-data-status=1, handle-never-received=0, init-value=CONST_t_cTRA_0:0}, required-interface=SR_ToggleReqAuthentForLoc
      RP_SR_TypeCondaMux: nonqueued-receiver-com-spec{data-element=TypeCondaMux, enable-update=0, handle-data-status=1, handle-never-received=0, init-value=CONST_TypeCondaMux_t_cMC_Mux_cMC_Mux_Indefini:0}, required-interface=SR_TypeCondaMux
      RP_SR_VehWshngSeqRawReq: nonqueued-receiver-com-spec{data-element=VehWshngSeqRawReq, enable-update=0, handle-data-status=1, handle-never-received=0, init-value=CONST_VehWshngSeqRawReq_t_cVehWshngSeq_cVehWshngSeq_NotRequested:0}, required-interface=SR_VehWshngSeqRawReq
      RP_SR_VitesseVehicule: nonqueued-receiver-com-spec{data-element=VitesseVehicule, enable-update=0, handle-data-status=1, handle-never-received=0, init-value=CONST_tWORD_0:0}, required-interface=SR_VitesseVehicule
      ASWC_M137_MSI: required-interface=AppModeInterface
    behavior IB_ASWC_M137: data-type-mapping=ApplicationModeMapping, handle-termination-and-restart=NO-SUPPORT
      ar-typed-per-instance-memorys:
        123 x data:
          PINVVMLSDCM_AlerteAbsenceClefML: type=tLOG, init-value=CONST_tLOG_0:0
          PINVVMLSDCM_AntiScanBSIActif: type=tLOG, init-value=CONST_tLOG_0:0
          PINVVMLSDCM_AppBadgeBMLStartPrec: type=tLOG, init-value=CONST_tLOG_0:0
          PINVVMLSDCM_AppBadgeBMLStopPrec: type=tLOG, init-value=CONST_tLOG_0:0
          PINVVMLSDCM_ApprUidNFCStartPrec: type=tLOG, init-value=CONST_tLOG_0:0
          PINVVMLSDCM_ApprUidNFCStopPrec: type=tLOG, init-value=CONST_tLOG_0:0
          PINVVMLSDCM_AuthentificationMLOk: type=tLOG, init-value=CONST_tLOG_0:0
          PINVVMLSDCM_AuthentMLouBU: type=tLOG, init-value=CONST_tLOG_0:0
          PINVVMLSDCM_BSIDeverrouillee: type=tLOG, init-value=CONST_tLOG_0:0
          PINVVMLSDCM_CondRtAppBadgeNFCSDCM: type=tLOG, init-value=CONST_tLOG_0:0
          PINVVMLSDCM_CondRtAppBadgeSDCM: type=tLOG, init-value=CONST_tLOG_0:0
          PINVVMLSDCM_CondRtApprUIdNFC: type=tLOG, init-value=CONST_tLOG_0:0
          PINVVMLSDCM_CryptUIdNFC1_{1..4}: type=tDWORD, init-value=CONST_tDWORD_0:0
          PINVVMLSDCM_CryptUIdNFC2_{1..4}: type=tDWORD, init-value=CONST_tDWORD_0:0
          PINVVMLSDCM_CryptUIdNFC3_{1..4}: type=tDWORD, init-value=CONST_tDWORD_0:0
          PINVVMLSDCM_CryptUIdNFC4_{1..4}: type=tDWORD, init-value=CONST_tDWORD_0:0
          PINVVMLSDCM_CryptUIdNFC5_{1..4}: type=tDWORD, init-value=CONST_tDWORD_0:0
          PINVVMLSDCM_DisplaySdStartingAutorIconPrec: type=tBYTE, init-value=CONST_tBYTE_0:0
          PINVVMLSDCM_DmdAppuiPushPrec: type=tLOG, init-value=CONST_tLOG_0:0
          PINVVMLSDCM_DmdAuthentTrspDiag: type=tLOG, init-value=CONST_tLOG_0:0
          PINVVMLSDCM_DmdAuthentTrspDiagPrec: type=tLOG, init-value=CONST_tLOG_0:0
          PINVVMLSDCM_DmdRetroPushDemPrec: type=t_cPushDem, init-value=CONST_PINVVMLSDCM_DmdRetroPushDemPrec_t_cPushDem_cPushDem_Eteint:0
          PINVVMLSDCM_DmdSecuKeyLearningPrec: type=tBYTE, init-value=CONST_tBYTE_0:0
          PINVVMLSDCM_DureeAlerteAbsenceClefML: type=tWORD, init-value=CONST_tWORD_0xFFFF:65535
          PINVVMLSDCM_EndOfDelayBeforeNFCReq: type=tLOG, init-value=CONST_tLOG_0:0
          PINVVMLSDCM_EtatAppr: type=tBYTE, init-value=CONST_tBYTE_0:0
          PINVVMLSDCM_EtatAutomateAuthentML: type=t_EtatAutomateAuthentML, init-value=0
          PINVVMLSDCM_EtatAutomateAuthentMLPrec: type=t_EtatAutomateAuthentML, init-value=0
          PINVVMLSDCM_EtatGMPPrec: type=t_GM_GMP, init-value=CONST_PINVVMLSDCM_EtatGMPPrec_t_GM_GMP_GM_GMPCoupe:1
          PINVVMLSDCM_EtatLocalisationMLPrec: type=tBILOG, init-value=CONST_tBILOG_0:0
          PINVVMLSDCM_EtatMoteurTournant: type=tLOG, init-value=CONST_tLOG_0:0
          PINVVMLSDCM_EtatPrincipalSEVPrec: type=t_SEV, init-value=CONST_PINVVMLSDCM_EtatPrincipalSEVPrec_t_SEV_SEV_Arret:105
          PINVVMLSDCM_FlagDecryptFinishCB: type=tLOG, init-value=CONST_tLOG_0:0
          PINVVMLSDCM_FlagDecryptStartCB: type=tLOG, init-value=CONST_tLOG_0:0
          PINVVMLSDCM_FlagDecryptUpdateCB: type=tLOG, init-value=CONST_tLOG_0:0
          PINVVMLSDCM_FlagEncryptFinishCB: type=tLOG, init-value=CONST_tLOG_0:0
          PINVVMLSDCM_FlagEncryptStartCB: type=tLOG, init-value=CONST_tLOG_0:0
          PINVVMLSDCM_FlagEncryptUpdateCB: type=tLOG, init-value=CONST_tLOG_0:0
          PINVVMLSDCM_LncDdeAuthentMLPrec: type=tLOG, init-value=CONST_tLOG_0:0
          PINVVMLSDCM_MemoDmdAppuiPush: type=tLOG, init-value=CONST_tLOG_0:0
          PINVVMLSDCM_NbrTentEchecApp: type=tBYTE, init-value=CONST_tBYTE_0:0
          PINVVMLSDCM_NFCUidTrouve: type=tLOG, init-value=CONST_tLOG_0:0
          PINVVMLSDCM_NotifyRxSdcmPrec: type=tBYTE, init-value=CONST_tBYTE_0:0
          PINVVMLSDCM_NumBadgeML: type=tBYTE, init-value=CONST_tBYTE_0:0
          PINVVMLSDCM_PorteOuvertePrec: type=tLOG, init-value=CONST_tLOG_0:0
          PINVVMLSDCM_RelanceEffectuee: type=tLOG, init-value=CONST_tLOG_0:0
          PINVVMLSDCM_ResDmdAuthentTrspDiag: type=t_cAuthent, init-value=3
          PINVVMLSDCM_RqBTStartingAutorizationPrec: type=tLOG, init-value=CONST_tLOG_0:0
          PINVVMLSDCM_SauvReqAuthNFCCard: type=tLOG, init-value=CONST_tLOG_0:0
          PINVVMLSDCM_SauvReqAuthNFCSD: type=tLOG, init-value=CONST_tLOG_0:0
          PINVVMLSDCM_SessionDiagEncoursPrec: type=tLOG, init-value=CONST_tLOG_0:0
          PINVVMLSDCM_StateAppBadgeNFCSDCM: type=tBYTE, init-value=CONST_tBYTE_0:0
          PINVVMLSDCM_StateSauvBadgeNFCSDCM: type=tBYTE, init-value=CONST_tBYTE_0:0
          PINVVMLSDCM_TAbsenceAuthent{1..4}: type=tBYTE, init-value=CONST_tBYTE_0:0
          PINVVMLSDCM_Tempo_ABSENCE_REP_APP_BADGE_SDCM: type=tBYTE, init-value=CONST_tBYTE_0:0
          PINVVMLSDCM_TempoAntiscanBSI: type=tWORD, init-value=CONST_tWORD_0:0
          PINVVMLSDCM_TempoAttenteRep: type=tBYTE, init-value=CONST_tBYTE_0:0
          PINVVMLSDCM_TempoAuthMLBU: type=tBYTE, init-value=CONST_tBYTE_0:0
          PINVVMLSDCM_TempoCalage: type=tWORD, init-value=CONST_tWORD_0:0
          PINVVMLSDCM_TempoDelayBeforeNFCReq: type=tBYTE, init-value=CONST_tBYTE_0:0
          PINVVMLSDCM_TempoDureeRelanceAuthentML: type=tWORD, init-value=CONST_tWORD_0:0
          PINVVMLSDCM_TempoInvitDepose: type=tBYTE, init-value=CONST_tBYTE_0:0
          PINVVMLSDCM_TempoMaintientAuthent: type=tBYTE, init-value=CONST_tBYTE_0:0
          PINVVMLSDCM_TempoPollingAuthentML: type=tBYTE, init-value=CONST_tBYTE_0:0
          PINVVMLSDCM_TempoPollingWashMode: type=tBYTE, init-value=CONST_tBYTE_0:0
          PINVVMLSDCM_TempoRelanceAuthent: type=tBYTE, init-value=CONST_tBYTE_0:0
          PINVVMLSDCM_TempoUIDNFC: type=tBYTE, init-value=CONST_tBYTE_0:0
          PINVVMLSDCM_TempoValiditeAuthML: type=tWORD, init-value=CONST_tWORD_0:0
          PINVVMLSDCM_TempoValidityAuthentNotif: type=tWORD, init-value=CONST_tWORD_0:0
          PINVVMLSDCM_ToggleAuthentBUPrec: type=tLOG, init-value=CONST_tLOG_0:0
          PINVVMLSDCM_ToggleErrorBUPrec: type=tLOG, init-value=CONST_tLOG_0:0
          PINVVMLSDCM_ToggleIdentBUPrec: type=tLOG, init-value=CONST_tLOG_0:0
          PINVVMLSDCM_ToggleLocIDMLIntFullPrec: type=tLOG, init-value=CONST_tLOG_0:0
          PINVVMLSDCM_ToggleReceiveSegMsgPrec: type=tLOG, init-value=CONST_tLOG_0:0
          PINVVMLSDCM_ToggleReqAuthentForLocPrec: type=tBYTE, init-value=CONST_tBYTE_0:0
          PINVVMLSDCM_ToggleReqLearnUIDTablePrec: type=tLOG, init-value=CONST_tLOG_0:0
          PINVVMLSDCM_ToggleSDCMStatePrec: type=tLOG, init-value=CONST_tLOG_0:0
          PINVVMLSDCM_TransitionArret: type=tLOG, init-value=CONST_tLOG_0:0
          PINVVMLSDCM_UIdNFC1_{1..4}: type=tDWORD, init-value=CONST_tDWORD_0:0
          PINVVMLSDCM_UIdNFC2_{1..4}: type=tDWORD, init-value=CONST_tDWORD_0:0
          PINVVMLSDCM_UIdNFC3_{1..4}: type=tDWORD, init-value=CONST_tDWORD_0:0
          PINVVMLSDCM_UIdNFC4_{1..4}: type=tDWORD, init-value=CONST_tDWORD_0:0
          PINVVMLSDCM_UIdNFC5_{1..4}: type=tDWORD, init-value=CONST_tDWORD_0:0
          PINVVMLSDCM_ValidityAuthentWithNotif: type=tLOG, init-value=CONST_tLOG_0:0
          PINVVMLSDCM_VhlVerrouille: type=tLOG, init-value=CONST_tLOG_0:0
          PINVVMLSDCM_VhlVerrouillePrec: type=tLOG, init-value=CONST_tLOG_0:0
          PINVVMLSDCM_VitesseVehiculePrec: type=tWORD, init-value=CONST_tWORD_0:0
          PINVVMLSDCM_WashingTunnelPollingStatus: type=tLOG, init-value=CONST_tLOG_0:0
          PINVVMLSDCM_WashModeActivated: type=tLOG, init-value=CONST_tLOG_0:0
          PINVVMLSDCM_WashModeNBAuthentNOK: type=tBYTE, init-value=CONST_tBYTE_0:0
      19 x operation invoked event:
        PP_CS_TRP_Notification_Authent_Result_OIE: start-on-event=RUNS_AuthentResult, operation=PP_CS_TRP_Notification.Authent_Result
        PP_CS_TRP_Notification_Cfg_Read_Result_OIE: start-on-event=RUNS_CfgReadResult, operation=PP_CS_TRP_Notification.Cfg_Read_Result
        PP_CS_TRP_Notification_Cfg_Write_Result_OIE: start-on-event=RUNS_CfgWriteResult, operation=PP_CS_TRP_Notification.Cfg_Write_Result
        PP_CS_TRP_Notification_Error_OIE: start-on-event=RUNS_Error, operation=PP_CS_TRP_Notification.Error
        PP_CS_TRP_Notification_Ident_Result_OIE: start-on-event=RUNS_IdentResult, operation=PP_CS_TRP_Notification.Ident_Result
        PP_CS_INVIO_BU_Command_Invio_AuthentRequest_OIE: start-on-event=RUNS_INVIO_AuthentRequest, operation=PP_CS_INVIO_BU_Command.Invio_AuthentRequest
        PP_CS_INVIO_Services_Invio_CalculerDataAuthent_OIE: start-on-event=RUNS_INVIO_CalculerDataAuthent, operation=PP_CS_INVIO_Services.Invio_CalculerDataAuthent
        PP_CS_INVIO_Services_Invio_CalculerRSK_OIE: start-on-event=RUNS_INVIO_CalculerRSK, operation=PP_CS_INVIO_Services.Invio_CalculerRSK
        PP_CS_INVIO_BU_Command_Invio_CfgReadRequest_OIE: start-on-event=RUNS_INVIO_CfgReadRequest, operation=PP_CS_INVIO_BU_Command.Invio_CfgReadRequest
        PP_CS_INVIO_BU_Command_Invio_CfgWriteRequest_OIE: start-on-event=RUNS_INVIO_CfgWriteRequest, operation=PP_CS_INVIO_BU_Command.Invio_CfgWriteRequest
        PP_CS_INVIO_Services_Invio_FinAppr_OIE: start-on-event=RUNS_INVIO_FinAppr, operation=PP_CS_INVIO_Services.Invio_FinAppr
        PP_CS_INVIO_Services_Invio_GetCIDAndStatus_OIE: start-on-event=RUNS_INVIO_GetCIDAndStatus, operation=PP_CS_INVIO_Services.Invio_GetCIDAndStatus
        PP_CS_INVIO_BU_Command_Invio_IdentRequest_OIE: start-on-event=RUNS_INVIO_IdentRequest, operation=PP_CS_INVIO_BU_Command.Invio_IdentRequest
        PP_CS_INVIO_Services_Invio_LocalisationMLEnCours_OIE: start-on-event=RUNS_INVIO_LocMLEnCours, operation=PP_CS_INVIO_Services.Invio_LocalisationMLEnCours
        PP_CS_INVIO_BU_Command_Invio_ReadRequest_OIE: start-on-event=RUNS_INVIO_ReadRequest, operation=PP_CS_INVIO_BU_Command.Invio_ReadRequest
        PP_CS_INVIO_MSGSEG_Invio_ReceiveSegMsg_OIE: start-on-event=RUNS_INVIO_ReceiveSegMsg, operation=PP_CS_INVIO_MSGSEG.Invio_ReceiveSegMsg
        PP_CS_INVIO_BU_Command_Invio_WriteRequest_OIE: start-on-event=RUNS_INVIO_WriteRequest, operation=PP_CS_INVIO_BU_Command.Invio_WriteRequest
        PP_CS_TRP_Notification_Read_Result_OIE: start-on-event=RUNS_ReadResult, operation=PP_CS_TRP_Notification.Read_Result
        PP_CS_TRP_Notification_Write_Result_OIE: start-on-event=RUNS_WriteResult, operation=PP_CS_TRP_Notification.Write_Result
      data received event ReqLearnUIDTableToSDCM_DRE: start-on-event=RUND_INVVMLSDCM_REQ_LEARN_UID_TABLE_TO_SDCM_041, data=RP_SR_ReqLearnUIDTableToSDCM.ReqLearnUIDTableToSDCM
      data received event SDCMCodeAppairRes_DRE: start-on-event=RUND_INVVMLSDCM_SDCM_STATE_20E, data=RP_SR_SDCMCodeAppairRes.SDCMCodeAppairRes
      timing event RUNA_INVVMLSDCM_Cyclic: start-on-event=RUNA_INVVMLSDCM, period=0.05
        disabled-mode:
          ASWC_M137_MSI.AppMode.APP_WAKEUP
          ASWC_M137_MSI.AppMode.APP_OFF
          ASWC_M137_MSI.AppMode.APP_SYNC_INIT1
          ASWC_M137_MSI.AppMode.APP_SYNC_INIT2
          ASWC_M137_MSI.AppMode.APP_CONFIG
      swc mode switch event RUNI_INVVMLSDCM_ENTRY: start-on-event=RUNI_INVVMLSDCM, activation=ON-ENTRY, mode=ASWC_M137_MSI.AppMode.APP_SYNC_INIT2
      explicit-inter-runnable-variables:
        42 x data:
          IINVVMLSDCM_AppBadgeBMLCauseNok: type=t_cCause, init-value=CONST_IINVVMLSDCM_AppBadgeBMLCauseNok_t_cCause_cCause_PasOperation:0
          IINVVMLSDCM_AppBadgeBMLCodeADC: type=tDWORD, init-value=CONST_tDWORD_0:0
          IINVVMLSDCM_AppBadgeBMLStart: type=tLOG, init-value=CONST_tLOG_0:0
          IINVVMLSDCM_AppBadgeBMLStatus: type=t_cRoutine, init-value=CONST_IINVVMLSDCM_AppBadgeBMLStatus_t_cRoutine_cRoutine_NonDemarre:0
          IINVVMLSDCM_AppBadgeBMLStop: type=tLOG, init-value=CONST_tLOG_0:0
          IINVVMLSDCM_ApprUidNFCCauseNok: type=t_cCause, init-value=CONST_IINVVMLSDCM_ApprUidNFCCauseNok_t_cCause_cCause_PasOperation:0
          IINVVMLSDCM_ApprUidNFCStart: type=tLOG, init-value=CONST_tLOG_0:0
          IINVVMLSDCM_ApprUidNFCStatus: type=t_cRoutine, init-value=CONST_IINVVMLSDCM_ApprUidNFCStatus_t_cRoutine_cRoutine_NonDemarre:0
          IINVVMLSDCM_ApprUidNFCStop: type=tLOG, init-value=CONST_tLOG_0:0
          IINVVMLSDCM_AuthentData: type=tDWORD, init-value=CONST_tDWORD_0:0
          IINVVMLSDCM_Cid{1..5}Status: type=tLOG, init-value=CONST_tLOG_0:0
          IINVVMLSDCM_CommandCode: type=tBYTE, init-value=CONST_tBYTE_0:0
          IINVVMLSDCM_ErrorCode: type=tBYTE, init-value=CONST_tBYTE_0:0
          IINVVMLSDCM_ResetBSI: type=tLOG, init-value=CONST_tLOG_0:0
          IINVVMLSDCM_SizeReceiveSegMsg: type=tWORD, init-value=CONST_tWORD_0:0
          IINVVMLSDCM_ToggleReceiveSegMsg: type=tLOG, init-value=CONST_tLOG_0:0
          IINVVMLSDCM_ToggleReqLearnUIDTableToSDCM: type=tLOG, init-value=CONST_tLOG_0:0
          IINVVMLSDCM_ToggleSDCMState: type=tLOG, init-value=CONST_tLOG_0:0
          IINVVMLSDCM_UIdNFC1_{1..4}: type=tDWORD, init-value=CONST_tDWORD_0:0
          IINVVMLSDCM_UIdNFC2_{1..4}: type=tDWORD, init-value=CONST_tDWORD_0:0
          IINVVMLSDCM_UIdNFC3_{1..4}: type=tDWORD, init-value=CONST_tDWORD_0:0
          IINVVMLSDCM_UIdNFC4_{1..4}: type=tDWORD, init-value=CONST_tDWORD_0:0
          IINVVMLSDCM_UIdNFC5_{1..4}: type=tDWORD, init-value=CONST_tDWORD_0:0
      29 x runnable:
        RUNA_INVVMLSDCM
          data-read-access:
            136 x access:
              dra_PRP_SR_IdentTrspBU_IdentTrspBU: accessed-variable=PRP_SR_IdentTrspBU.IdentTrspBU
              dra_PRP_SR_ToggleAuthentBU_ToggleAuthentBU: accessed-variable=PRP_SR_ToggleAuthentBU.ToggleAuthentBU
              dra_PRP_SR_ToggleErrorBU_ToggleErrorBU: accessed-variable=PRP_SR_ToggleErrorBU.ToggleErrorBU
              dra_PRP_SR_ToggleIdentBU_ToggleIdentBU: accessed-variable=PRP_SR_ToggleIdentBU.ToggleIdentBU
              dra_RP_SR_ApprentissageCleEnCours_ApprentissageCleEnCours: accessed-variable=RP_SR_ApprentissageCleEnCours.ApprentissageCleEnCours
              dra_RP_SR_AuthentificatedDeviceNum_AuthentificatedDeviceNum: accessed-variable=RP_SR_AuthentificatedDeviceNum.AuthentificatedDeviceNum
              dra_RP_SR_BSIDeverrouillee_BSIDeverrouillee: accessed-variable=RP_SR_BSIDeverrouillee.BSIDeverrouillee
              dra_RP_SR_CFG_BSI_VIERGE_CFG_BSI_VIERGE: accessed-variable=RP_SR_CFG_BSI_VIERGE.CFG_BSI_VIERGE
              dra_RP_SR_CFG_IdentPlip_CFG_IdentPlip{1..5}: accessed-variable=RP_SR_CFG_IdentPlip.CFG_IdentPlip{1..5}
              dra_RP_SR_CFG_IdentTrsp_CFG_IdentTrsp{1..5}: accessed-variable=RP_SR_CFG_IdentTrsp.CFG_IdentTrsp{1..5}
              dra_RP_SR_CFG_NbPlipAppris_CFG_NbPlipAppris: accessed-variable=RP_SR_CFG_NbPlipAppris.CFG_NbPlipAppris
              dra_RP_SR_CFG_NbTrspAppris_CFG_NbTrspAppris: accessed-variable=RP_SR_CFG_NbTrspAppris.CFG_NbTrspAppris
              dra_RP_SR_CFG_NumBadge_CFG_NumBadge{1..5}: accessed-variable=RP_SR_CFG_NumBadge.CFG_NumBadge{1..5}
              dra_RP_SR_CidStatus_Cid{1..5}Status: accessed-variable=RP_SR_CidStatus.Cid{1..5}Status
              dra_RP_SR_CodeADC_CodeADC{1..4}: accessed-variable=RP_SR_CodeADC.CodeADC{1..4}
              dra_RP_SR_CodeVIN_{15..17}_CodeVIN_{15..17}: accessed-variable=RP_SR_CodeVIN_{15..17}.CodeVIN_{15..17}
              dra_RP_SR_ConducteurAuthDsHAB_ConducteurAuthDsHAB: accessed-variable=RP_SR_ConducteurAuthDsHAB.ConducteurAuthDsHAB
              dra_RP_SR_DisplaySdStartingAutorIcon_DisplaySdStartingAutorIcon: accessed-variable=RP_SR_DisplaySdStartingAutorIcon.DisplaySdStartingAutorIcon
              dra_RP_SR_DmdAppuiPush_DmdAppuiPush: accessed-variable=RP_SR_DmdAppuiPush.DmdAppuiPush
              dra_RP_SR_DmdAuthentTrspDiag_DmdAuthentTrspDiag: accessed-variable=RP_SR_DmdAuthentTrspDiag.DmdAuthentTrspDiag
              dra_RP_SR_SecuApprData_DmdSecuKeyLearning: accessed-variable=RP_SR_SecuApprData.DmdSecuKeyLearning
              dra_RP_SR_DysfVitesseVehicule_DysfVitesseVehicule: accessed-variable=RP_SR_DysfVitesseVehicule.DysfVitesseVehicule
              dra_RP_SR_EtatGMP_EtatGMP: accessed-variable=RP_SR_EtatGMP.EtatGMP
              dra_RP_SR_EtatMenuINV_ADSD_EtatMenuINV_ADSD: accessed-variable=RP_SR_EtatMenuINV_ADSD.EtatMenuINV_ADSD
              dra_RP_SR_EtatPrincipalSEV_EtatPrincipalSEV: accessed-variable=RP_SR_EtatPrincipalSEV.EtatPrincipalSEV
              dra_RP_SR_InterMemoDefauts_InterMemoDefauts: accessed-variable=RP_SR_InterMemoDefauts.InterMemoDefauts
              dra_RP_SR_SecuApprData_KeyLearningValidFlag: accessed-variable=RP_SR_SecuApprData.KeyLearningValidFlag
              dra_RP_SR_LncDdeAuthentML_LncDdeAuthentML: accessed-variable=RP_SR_LncDdeAuthentML.LncDdeAuthentML
              dra_RP_SR_HfResultatLocIDMLIntFull_LocIDMLIntFull: accessed-variable=RP_SR_HfResultatLocIDMLIntFull.LocIDMLIntFull
              dra_RP_SR_NotifyRxSdcm_NotifyRxSdcm: accessed-variable=RP_SR_NotifyRxSdcm.NotifyRxSdcm
              dra_RP_SR_PhaseVieLS_PhaseVieLS: accessed-variable=RP_SR_PhaseVieLS.PhaseVieLS
              dra_RP_SR_ReqLearnUIDTableToSDCM_ReqLearnUIDTableToSDCM: accessed-variable=RP_SR_ReqLearnUIDTableToSDCM.ReqLearnUIDTableToSDCM
              dra_RP_SR_AuthentResult_ResAuthentBTSD: accessed-variable=RP_SR_AuthentResult.ResAuthentBTSD
              dra_RP_SR_AuthentResult_ResAuthentCID: accessed-variable=RP_SR_AuthentResult.ResAuthentCID
              dra_RP_SR_AuthentResult_ResAuthentNFCCard: accessed-variable=RP_SR_AuthentResult.ResAuthentNFCCard
              dra_RP_SR_AuthentResult_ResAuthentNFCSD: accessed-variable=RP_SR_AuthentResult.ResAuthentNFCSD
              dra_RP_SR_BluetoothRequest_RqBTStartingAutorization: accessed-variable=RP_SR_BluetoothRequest.RqBTStartingAutorization
              dra_RP_SR_SAV_CondaRealisee_SAV_CondaRealisee: accessed-variable=RP_SR_SAV_CondaRealisee.SAV_CondaRealisee
              dra_RP_SR_SAV_EtatOuvrants_SAV_EtatOuvrants: accessed-variable=RP_SR_SAV_EtatOuvrants.SAV_EtatOuvrants
              dra_RP_SR_SdcmAuthorisation_SdcmAuthorisation: accessed-variable=RP_SR_SdcmAuthorisation.SdcmAuthorisation
              dra_RP_SR_SDCMBlacklistingTask_SDCMBlacklistingTask: accessed-variable=RP_SR_SDCMBlacklistingTask.SDCMBlacklistingTask
              dra_RP_SR_SDCMCodeAppairRes_SDCMCodeAppairRes: accessed-variable=RP_SR_SDCMCodeAppairRes.SDCMCodeAppairRes
              dra_RP_SR_SEC_ConfigSEV_SEC_ConfigSEV: accessed-variable=RP_SR_SEC_ConfigSEV.SEC_ConfigSEV
              dra_RP_SR_SessionDiagEncours_SessionDiagEncours: accessed-variable=RP_SR_SessionDiagEncours.SessionDiagEncours
              dra_RP_SR_SEVDem_SEVDem: accessed-variable=RP_SR_SEVDem.SEVDem
              dra_RP_SR_HfResultatLocIDMLIntFull_ToggleLocIDMLIntFull: accessed-variable=RP_SR_HfResultatLocIDMLIntFull.ToggleLocIDMLIntFull
              dra_RP_SR_ToggleReqAuthentForLoc_ToggleReqAuthentForLoc: accessed-variable=RP_SR_ToggleReqAuthentForLoc.ToggleReqAuthentForLoc
              dra_RP_SR_TypeCondaMux_TypeCondaMux: accessed-variable=RP_SR_TypeCondaMux.TypeCondaMux
              dra_RP_SR_VehWshngSeqRawReq_VehWshngSeqRawReq: accessed-variable=RP_SR_VehWshngSeqRawReq.VehWshngSeqRawReq
              dra_RP_SR_VitesseVehicule_VitesseVehicule: accessed-variable=RP_SR_VitesseVehicule.VitesseVehicule
              dra_RP_SR_CFG_GEN_ISK16_CFG_GEN_ISK16: accessed-variable=RP_SR_CFG_GEN_ISK16.CFG_GEN_ISK16
              dra_RP_SR_CFG_LEVIER_BV_CFG_LEVIER_BV: accessed-variable=RP_SR_CFG_LEVIER_BV.CFG_LEVIER_BV
              dra_RP_SR_CFG_OPTION_NFC_CFG_OPTION_NFC: accessed-variable=RP_SR_CFG_OPTION_NFC.CFG_OPTION_NFC
              dra_RP_SR_CFG_OPTION_WLC_CFG_OPTION_WLC: accessed-variable=RP_SR_CFG_OPTION_WLC.CFG_OPTION_WLC
              dra_RP_SR_CFG_SMARTDEVICE_BY_SDCM_CFG_SMARTDEVICE_BY_SDCM: accessed-variable=RP_SR_CFG_SMARTDEVICE_BY_SDCM.CFG_SMARTDEVICE_BY_SDCM
              dra_RP_SR_CFG_TYPE_CHAINE_TRACTION_CFG_TYPE_CHAINE_TRACTION: accessed-variable=RP_SR_CFG_TYPE_CHAINE_TRACTION.CFG_TYPE_CHAINE_TRACTION
              dra_RP_SR_CFG_TYPE_CLE_CFG_TYPE_CLE: accessed-variable=RP_SR_CFG_TYPE_CLE.CFG_TYPE_CLE
              dra_RP_SR_CFG_TYPE_STT_CFG_TYPE_STT: accessed-variable=RP_SR_CFG_TYPE_STT.CFG_TYPE_STT
              dra_RP_SR_CINVCOM_DUREE_ANTISCAN_CODE_BSI_CINVCOM_DUREE_ANTISCAN_CODE_BSI: accessed-variable=RP_SR_CINVCOM_DUREE_ANTISCAN_CODE_BSI.CINVCOM_DUREE_ANTISCAN_CODE_BSI
              dra_RP_SR_CINVVMLAPPTRSP_NB_ESSAIS_IDENT_BU_CINVVMLAPPTRSP_NB_ESSAIS_IDENT_BU: accessed-variable=RP_SR_CINVVMLAPPTRSP_NB_ESSAIS_IDENT_BU.CINVVMLAPPTRSP_NB_ESSAIS_IDENT_BU
              dra_RP_SR_CINVVMLSDCM_ABSENCE_REP_APP_BADGE_SDCM_CINVVMLSDCM_ABSENCE_REP_APP_BADGE_SDCM: accessed-variable=RP_SR_CINVVMLSDCM_ABSENCE_REP_APP_BADGE_SDCM.CINVVMLSDCM_ABSENCE_REP_APP_BADGE_SDCM
              dra_RP_SR_CINVVMLSDCM_BYPASS_AUTHENT_VIA_SDBT_CINVVMLSDCM_BYPASS_AUTHENT_VIA_SDBT: accessed-variable=RP_SR_CINVVMLSDCM_BYPASS_AUTHENT_VIA_SDBT.CINVVMLSDCM_BYPASS_AUTHENT_VIA_SDBT
              dra_RP_SR_CINVVMLSDCM_DELAY_LAUNCH_NFC_REQ_CINVVMLSDCM_DELAY_LAUNCH_NFC_REQ: accessed-variable=RP_SR_CINVVMLSDCM_DELAY_LAUNCH_NFC_REQ.CINVVMLSDCM_DELAY_LAUNCH_NFC_REQ
              dra_RP_SR_CINVVMLSDCM_DUREE_ALERTE_PERTE_IDENT_CINVVMLSDCM_DUREE_ALERTE_PERTE_IDENT: accessed-variable=RP_SR_CINVVMLSDCM_DUREE_ALERTE_PERTE_IDENT.CINVVMLSDCM_DUREE_ALERTE_PERTE_IDENT
              dra_RP_SR_CINVVMLSDCM_DUREE_RELANCE_AUTH_ML_CINVVMLSDCM_DUREE_RELANCE_AUTH_ML: accessed-variable=RP_SR_CINVVMLSDCM_DUREE_RELANCE_AUTH_ML.CINVVMLSDCM_DUREE_RELANCE_AUTH_ML
              dra_RP_SR_CINVVMLSDCM_NB_ESSAIS_AUTHENT_BU_CINVVMLSDCM_NB_ESSAIS_AUTHENT_BU: accessed-variable=RP_SR_CINVVMLSDCM_NB_ESSAIS_AUTHENT_BU.CINVVMLSDCM_NB_ESSAIS_AUTHENT_BU
              dra_RP_SR_CINVVMLSDCM_SDCM_TMAX_AUTH_ML_BU_CINVVMLSDCM_SDCM_TMAX_AUTH_ML_BU: accessed-variable=RP_SR_CINVVMLSDCM_SDCM_TMAX_AUTH_ML_BU.CINVVMLSDCM_SDCM_TMAX_AUTH_ML_BU
              dra_RP_SR_CINVVMLSDCM_SEUIL_VIT_RELANCE_AUTHENT_CINVVMLSDCM_SEUIL_VIT_RELANCE_AUTHENT: accessed-variable=RP_SR_CINVVMLSDCM_SEUIL_VIT_RELANCE_AUTHENT.CINVVMLSDCM_SEUIL_VIT_RELANCE_AUTHENT
              dra_RP_SR_CINVVMLSDCM_TEMPO_ATTENTE_UID_NFC_CINVVMLSDCM_TEMPO_ATTENTE_UID_NFC: accessed-variable=RP_SR_CINVVMLSDCM_TEMPO_ATTENTE_UID_NFC.CINVVMLSDCM_TEMPO_ATTENTE_UID_NFC
              dra_RP_SR_CINVVMLSDCM_TEMPO_CALAGE_CINVVMLSDCM_TEMPO_CALAGE: accessed-variable=RP_SR_CINVVMLSDCM_TEMPO_CALAGE.CINVVMLSDCM_TEMPO_CALAGE
              dra_RP_SR_CINVVMLSDCM_TEMPO_RELANCE_AUTHENT_CINVVMLSDCM_TEMPO_RELANCE_AUTHENT: accessed-variable=RP_SR_CINVVMLSDCM_TEMPO_RELANCE_AUTHENT.CINVVMLSDCM_TEMPO_RELANCE_AUTHENT
              dra_RP_SR_CINVVMLSDCM_TEMPO_REQ_AUTHENT_CINVVMLSDCM_TEMPO_REQ_AUTHENT: accessed-variable=RP_SR_CINVVMLSDCM_TEMPO_REQ_AUTHENT.CINVVMLSDCM_TEMPO_REQ_AUTHENT
              dra_RP_SR_CINVVMLSDCM_TEMPO_VALIDITE_AUTHENT_CINVVMLSDCM_TEMPO_VALIDITE_AUTHENT: accessed-variable=RP_SR_CINVVMLSDCM_TEMPO_VALIDITE_AUTHENT.CINVVMLSDCM_TEMPO_VALIDITE_AUTHENT
              dra_RP_SR_CINVVMLSDCM_TEMPO_VALIDITY_NOTIF_CINVVMLSDCM_TEMPO_VALIDITY_NOTIF: accessed-variable=RP_SR_CINVVMLSDCM_TEMPO_VALIDITY_NOTIF.CINVVMLSDCM_TEMPO_VALIDITY_NOTIF
              dra_RP_SR_CINVVMLSDCM_TIMEOUT_POLLING_AUTHENT_ML_CINVVMLSDCM_TIMEOUT_POLLING_AUTHENT_ML: accessed-variable=RP_SR_CINVVMLSDCM_TIMEOUT_POLLING_AUTHENT_ML.CINVVMLSDCM_TIMEOUT_POLLING_AUTHENT_ML
              dra_RP_SR_CINVVMLSDCM_TMAX_AUTH_CID_CINVVMLSDCM_TMAX_AUTH_CID: accessed-variable=RP_SR_CINVVMLSDCM_TMAX_AUTH_CID.CINVVMLSDCM_TMAX_AUTH_CID
              dra_RP_SR_CINVVMLSDCM_TMAX_AUTH_NFC_CARD_CINVVMLSDCM_TMAX_AUTH_NFC_CARD: accessed-variable=RP_SR_CINVVMLSDCM_TMAX_AUTH_NFC_CARD.CINVVMLSDCM_TMAX_AUTH_NFC_CARD
              dra_RP_SR_CINVVMLSDCM_TMAX_AUTH_SD_BT_CINVVMLSDCM_TMAX_AUTH_SD_BT: accessed-variable=RP_SR_CINVVMLSDCM_TMAX_AUTH_SD_BT.CINVVMLSDCM_TMAX_AUTH_SD_BT
              dra_RP_SR_CINVVMLSDCM_WASH_MODE_ACTIV_AUTHENT_CINVVMLSDCM_WASH_MODE_ACTIV_AUTHENT: accessed-variable=RP_SR_CINVVMLSDCM_WASH_MODE_ACTIV_AUTHENT.CINVVMLSDCM_WASH_MODE_ACTIV_AUTHENT
              dra_RP_SR_CINVVMLSDCM_WASH_MODE_NB_RETRY_CINVVMLSDCM_WASH_MODE_NB_RETRY: accessed-variable=RP_SR_CINVVMLSDCM_WASH_MODE_NB_RETRY.CINVVMLSDCM_WASH_MODE_NB_RETRY
              dra_RP_SR_CINVVMLSDCM_WASH_MODE_POLLING_TIMEOUT_CINVVMLSDCM_WASH_MODE_POLLING_TIMEOUT: accessed-variable=RP_SR_CINVVMLSDCM_WASH_MODE_POLLING_TIMEOUT.CINVVMLSDCM_WASH_MODE_POLLING_TIMEOUT
              dra_PRP_SR_AppuiPushTraite_AppuiPushTraite: accessed-variable=PRP_SR_AppuiPushTraite.AppuiPushTraite
              dra_PRP_SR_AuthentBUDemandee_AuthentBUDemandee: accessed-variable=PRP_SR_AuthentBUDemandee.AuthentBUDemandee
              dra_PRP_SR_AuthentificationBU_AuthentificationBU: accessed-variable=PRP_SR_AuthentificationBU.AuthentificationBU
              dra_PRP_SR_AuthentificationBUMux_AuthentificationBUMux: accessed-variable=PRP_SR_AuthentificationBUMux.AuthentificationBUMux
              dra_PRP_SR_AuthentificationML_AuthentificationML: accessed-variable=PRP_SR_AuthentificationML.AuthentificationML
              dra_PRP_SR_AuthentificationMLnonSDF_AuthentificationMLnonSDF: accessed-variable=PRP_SR_AuthentificationMLnonSDF.AuthentificationMLnonSDF
              dra_PRP_SR_AuthentMLDemandee_AuthentMLDemandee: accessed-variable=PRP_SR_AuthentMLDemandee.AuthentMLDemandee
              dra_PRP_SR_DmdAffIHMAuthent_DmdAffIHMAuthent: accessed-variable=PRP_SR_DmdAffIHMAuthent.DmdAffIHMAuthent
              dra_PRP_SR_DmdAuthentBU_DmdAuthentBU: accessed-variable=PRP_SR_DmdAuthentBU.DmdAuthentBU
              dra_PRP_SR_DmdIdentBU_DmdIdentBU: accessed-variable=PRP_SR_DmdIdentBU.DmdIdentBU
              dra_PRP_SR_AnimationPushDem_DmdPoumonagePushDem: accessed-variable=PRP_SR_AnimationPushDem.DmdPoumonagePushDem
              dra_PRP_SR_AnimationPushDem_DmdRetroPushDem: accessed-variable=PRP_SR_AnimationPushDem.DmdRetroPushDem
              dra_PRP_SR_EtatLocalisationML_EtatLocalisationML: accessed-variable=PRP_SR_EtatLocalisationML.EtatLocalisationML
              dra_PRP_SR_IdentBUDemandee_IdentBUDemandee: accessed-variable=PRP_SR_IdentBUDemandee.IdentBUDemandee
              dra_PRP_SR_LastIdUsedToStart_LastNumIdUsedToStart: accessed-variable=PRP_SR_LastIdUsedToStart.LastNumIdUsedToStart
              dra_PRP_SR_LastIdUsedToStart_LastTypeIdUsedToStart: accessed-variable=PRP_SR_LastIdUsedToStart.LastTypeIdUsedToStart
              dra_PRP_SR_NbNFCUidAppris_NbNFCUidAppris: accessed-variable=PRP_SR_NbNFCUidAppris.NbNFCUidAppris
              dra_PRP_SR_NFCUidLearningEcuState_NFCUidLearningEcuState: accessed-variable=PRP_SR_NFCUidLearningEcuState.NFCUidLearningEcuState
              dra_PRP_SR_NoIMLAuthentOnStartRequest_NoIMLAuthentOnStartRequest: accessed-variable=PRP_SR_NoIMLAuthentOnStartRequest.NoIMLAuthentOnStartRequest
              dra_PRP_SR_PresenceClefAppriseBU_PresenceClefAppriseBU: accessed-variable=PRP_SR_PresenceClefAppriseBU.PresenceClefAppriseBU
              dra_PRP_SR_ReqAuthentBTSD_ReqAuthentBTSD: accessed-variable=PRP_SR_ReqAuthentBTSD.ReqAuthentBTSD
              dra_PRP_SR_ReqAuthentCID_ReqAuthentCID: accessed-variable=PRP_SR_ReqAuthentCID.ReqAuthentCID
              dra_PRP_SR_ReqAuthentNFCCard_ReqAuthentNFCCard: accessed-variable=PRP_SR_ReqAuthentNFCCard.ReqAuthentNFCCard
              dra_PRP_SR_ReqAuthentNFCSD_ReqAuthentNFCSD: accessed-variable=PRP_SR_ReqAuthentNFCSD.ReqAuthentNFCSD
              dra_PRP_SR_ReqLearnUIDTableBSI_ReqLearnUIDTableToBSI: accessed-variable=PRP_SR_ReqLearnUIDTableBSI.ReqLearnUIDTableToBSI
              dra_PRP_SR_SDCMBlacklistingRq_SDCMBlacklistingRq: accessed-variable=PRP_SR_SDCMBlacklistingRq.SDCMBlacklistingRq
              dra_PRP_SR_SDCMProg_SDCMCodeNumber: accessed-variable=PRP_SR_SDCMProg.SDCMCodeNumber
              dra_PRP_SR_SDCMProg_SDCMPackageCounter: accessed-variable=PRP_SR_SDCMProg.SDCMPackageCounter
              dra_PRP_SR_SDCMProg_SDCMProgCodelb: accessed-variable=PRP_SR_SDCMProg.SDCMProgCodelb
              dra_PRP_SR_SDCMProg_SDCMProgCodemb: accessed-variable=PRP_SR_SDCMProg.SDCMProgCodemb
              dra_PRP_SR_SDCMUnblacklistingRq_SDCMUnblacklistingRq: accessed-variable=PRP_SR_SDCMUnblacklistingRq.SDCMUnblacklistingRq
              dra_PRP_SR_SmartDeviceActivation_SmartDeviceActivation: accessed-variable=PRP_SR_SmartDeviceActivation.SmartDeviceActivation
              dra_PRP_SR_StatutApprNFCUid_StatutApprNFCUid: accessed-variable=PRP_SR_StatutApprNFCUid.StatutApprNFCUid
              dra_PRP_SR_HfResultatAuthentML_ToggleAuthentML: accessed-variable=PRP_SR_HfResultatAuthentML.ToggleAuthentML
          data-write-access:
            34 x access:
              dwa_PRP_SR_AppuiPushTraite_AppuiPushTraite: accessed-variable=PRP_SR_AppuiPushTraite.AppuiPushTraite
              dwa_PRP_SR_AuthentBUDemandee_AuthentBUDemandee: accessed-variable=PRP_SR_AuthentBUDemandee.AuthentBUDemandee
              dwa_PRP_SR_AuthentificationBU_AuthentificationBU: accessed-variable=PRP_SR_AuthentificationBU.AuthentificationBU
              dwa_PRP_SR_AuthentificationBUMux_AuthentificationBUMux: accessed-variable=PRP_SR_AuthentificationBUMux.AuthentificationBUMux
              dwa_PRP_SR_AuthentificationML_AuthentificationML: accessed-variable=PRP_SR_AuthentificationML.AuthentificationML
              dwa_PRP_SR_AuthentificationMLnonSDF_AuthentificationMLnonSDF: accessed-variable=PRP_SR_AuthentificationMLnonSDF.AuthentificationMLnonSDF
              dwa_PRP_SR_AuthentMLDemandee_AuthentMLDemandee: accessed-variable=PRP_SR_AuthentMLDemandee.AuthentMLDemandee
              dwa_PRP_SR_DmdAffIHMAuthent_DmdAffIHMAuthent: accessed-variable=PRP_SR_DmdAffIHMAuthent.DmdAffIHMAuthent
              dwa_PRP_SR_DmdAuthentBU_DmdAuthentBU: accessed-variable=PRP_SR_DmdAuthentBU.DmdAuthentBU
              dwa_PRP_SR_DmdIdentBU_DmdIdentBU: accessed-variable=PRP_SR_DmdIdentBU.DmdIdentBU
              dwa_PRP_SR_AnimationPushDem_DmdPoumonagePushDem: accessed-variable=PRP_SR_AnimationPushDem.DmdPoumonagePushDem
              dwa_PRP_SR_AnimationPushDem_DmdRetroPushDem: accessed-variable=PRP_SR_AnimationPushDem.DmdRetroPushDem
              dwa_PRP_SR_EtatLocalisationML_EtatLocalisationML: accessed-variable=PRP_SR_EtatLocalisationML.EtatLocalisationML
              dwa_PRP_SR_IdentBUDemandee_IdentBUDemandee: accessed-variable=PRP_SR_IdentBUDemandee.IdentBUDemandee
              dwa_PRP_SR_LastIdUsedToStart_LastNumIdUsedToStart: accessed-variable=PRP_SR_LastIdUsedToStart.LastNumIdUsedToStart
              dwa_PRP_SR_LastIdUsedToStart_LastTypeIdUsedToStart: accessed-variable=PRP_SR_LastIdUsedToStart.LastTypeIdUsedToStart
              dwa_PRP_SR_NbNFCUidAppris_NbNFCUidAppris: accessed-variable=PRP_SR_NbNFCUidAppris.NbNFCUidAppris
              dwa_PRP_SR_NFCUidLearningEcuState_NFCUidLearningEcuState: accessed-variable=PRP_SR_NFCUidLearningEcuState.NFCUidLearningEcuState
              dwa_PRP_SR_NoIMLAuthentOnStartRequest_NoIMLAuthentOnStartRequest: accessed-variable=PRP_SR_NoIMLAuthentOnStartRequest.NoIMLAuthentOnStartRequest
              dwa_PRP_SR_PresenceClefAppriseBU_PresenceClefAppriseBU: accessed-variable=PRP_SR_PresenceClefAppriseBU.PresenceClefAppriseBU
              dwa_PRP_SR_ReqAuthentBTSD_ReqAuthentBTSD: accessed-variable=PRP_SR_ReqAuthentBTSD.ReqAuthentBTSD
              dwa_PRP_SR_ReqAuthentCID_ReqAuthentCID: accessed-variable=PRP_SR_ReqAuthentCID.ReqAuthentCID
              dwa_PRP_SR_ReqAuthentNFCCard_ReqAuthentNFCCard: accessed-variable=PRP_SR_ReqAuthentNFCCard.ReqAuthentNFCCard
              dwa_PRP_SR_ReqAuthentNFCSD_ReqAuthentNFCSD: accessed-variable=PRP_SR_ReqAuthentNFCSD.ReqAuthentNFCSD
              dwa_PRP_SR_ReqLearnUIDTableBSI_ReqLearnUIDTableToBSI: accessed-variable=PRP_SR_ReqLearnUIDTableBSI.ReqLearnUIDTableToBSI
              dwa_PRP_SR_SDCMBlacklistingRq_SDCMBlacklistingRq: accessed-variable=PRP_SR_SDCMBlacklistingRq.SDCMBlacklistingRq
              dwa_PRP_SR_SDCMProg_SDCMCodeNumber: accessed-variable=PRP_SR_SDCMProg.SDCMCodeNumber
              dwa_PRP_SR_SDCMProg_SDCMPackageCounter: accessed-variable=PRP_SR_SDCMProg.SDCMPackageCounter
              dwa_PRP_SR_SDCMProg_SDCMProgCodelb: accessed-variable=PRP_SR_SDCMProg.SDCMProgCodelb
              dwa_PRP_SR_SDCMProg_SDCMProgCodemb: accessed-variable=PRP_SR_SDCMProg.SDCMProgCodemb
              dwa_PRP_SR_SDCMUnblacklistingRq_SDCMUnblacklistingRq: accessed-variable=PRP_SR_SDCMUnblacklistingRq.SDCMUnblacklistingRq
              dwa_PRP_SR_SmartDeviceActivation_SmartDeviceActivation: accessed-variable=PRP_SR_SmartDeviceActivation.SmartDeviceActivation
              dwa_PRP_SR_StatutApprNFCUid_StatutApprNFCUid: accessed-variable=PRP_SR_StatutApprNFCUid.StatutApprNFCUid
              dwa_PRP_SR_HfResultatAuthentML_ToggleAuthentML: accessed-variable=PRP_SR_HfResultatAuthentML.ToggleAuthentML
          read-local-variables:
            38 x access:
              rlv_IINVVMLSDCM_AppBadgeBMLCodeADC: accessed-variable=IINVVMLSDCM_AppBadgeBMLCodeADC
              rlv_IINVVMLSDCM_AppBadgeBMLStart: accessed-variable=IINVVMLSDCM_AppBadgeBMLStart
              rlv_IINVVMLSDCM_AppBadgeBMLStop: accessed-variable=IINVVMLSDCM_AppBadgeBMLStop
              rlv_IINVVMLSDCM_ApprUidNFCStart: accessed-variable=IINVVMLSDCM_ApprUidNFCStart
              rlv_IINVVMLSDCM_ApprUidNFCStop: accessed-variable=IINVVMLSDCM_ApprUidNFCStop
              rlv_IINVVMLSDCM_AuthentData: accessed-variable=IINVVMLSDCM_AuthentData
              rlv_IINVVMLSDCM_Cid{1..5}Status: accessed-variable=IINVVMLSDCM_Cid{1..5}Status
              rlv_IINVVMLSDCM_CommandCode: accessed-variable=IINVVMLSDCM_CommandCode
              rlv_IINVVMLSDCM_ErrorCode: accessed-variable=IINVVMLSDCM_ErrorCode
              rlv_IINVVMLSDCM_ResetBSI: accessed-variable=IINVVMLSDCM_ResetBSI
              rlv_IINVVMLSDCM_SizeReceiveSegMsg: accessed-variable=IINVVMLSDCM_SizeReceiveSegMsg
              rlv_IINVVMLSDCM_ToggleReceiveSegMsg: accessed-variable=IINVVMLSDCM_ToggleReceiveSegMsg
              rlv_IINVVMLSDCM_ToggleReqLearnUIDTableToSDCM: accessed-variable=IINVVMLSDCM_ToggleReqLearnUIDTableToSDCM
              rlv_IINVVMLSDCM_ToggleSDCMState: accessed-variable=IINVVMLSDCM_ToggleSDCMState
              rlv_IINVVMLSDCM_UIdNFC1_{1..4}: accessed-variable=IINVVMLSDCM_UIdNFC1_{1..4}
              rlv_IINVVMLSDCM_UIdNFC2_{1..4}: accessed-variable=IINVVMLSDCM_UIdNFC2_{1..4}
              rlv_IINVVMLSDCM_UIdNFC3_{1..4}: accessed-variable=IINVVMLSDCM_UIdNFC3_{1..4}
              rlv_IINVVMLSDCM_UIdNFC4_{1..4}: accessed-variable=IINVVMLSDCM_UIdNFC4_{1..4}
              rlv_IINVVMLSDCM_UIdNFC5_{1..4}: accessed-variable=IINVVMLSDCM_UIdNFC5_{1..4}
          7 x sync call, all with timeout=0:
            sscp_RUNA_INVVMLSDCM_RP_CS_TRP_Command_Authent_Request: operation=RP_CS_TRP_Command.Authent_Request
            sscp_RUNA_INVVMLSDCM_RP_CS_AlerteIHM_Cmd: operation=RP_CS_AlerteIHM.Cmd
            sscp_RUNA_INVVMLSDCM_RP_CS_GetFctNetworkStatus_Get: operation=RP_CS_GetFctNetworkStatus.Get
            sscp_RUNA_INVVMLSDCM_RP_CS_TRP_Command_Ident_Request: operation=RP_CS_TRP_Command.Ident_Request
            sscp_RUNA_INVVMLSDCM_RP_CS_ISOTP_MSGSEG_ISOTP_SendSegMsg: operation=RP_CS_ISOTP_MSGSEG.ISOTP_SendSegMsg
            sscp_RUNA_INVVMLSDCM_RP_CS_NVDM_WR_APP_NvDM_WrApp_Block: operation=RP_CS_NVDM_WR_APP.NvDM_WrApp_Block
            sscp_RUNA_INVVMLSDCM_RP_CS_ResAuthentDiag_Result: operation=RP_CS_ResAuthentDiag.Result
          written-local-variables:
            10 x access:
              wlv_IINVVMLSDCM_AppBadgeBMLCauseNok: accessed-variable=IINVVMLSDCM_AppBadgeBMLCauseNok
              wlv_IINVVMLSDCM_AppBadgeBMLStatus: accessed-variable=IINVVMLSDCM_AppBadgeBMLStatus
              wlv_IINVVMLSDCM_ApprUidNFCCauseNok: accessed-variable=IINVVMLSDCM_ApprUidNFCCauseNok
              wlv_IINVVMLSDCM_ApprUidNFCStatus: accessed-variable=IINVVMLSDCM_ApprUidNFCStatus
              wlv_IINVVMLSDCM_Cid{1..5}Status: accessed-variable=IINVVMLSDCM_Cid{1..5}Status
              wlv_IINVVMLSDCM_ResetBSI: accessed-variable=IINVVMLSDCM_ResetBSI
        RUND_INVVMLSDCM_REQ_LEARN_UID_TABLE_TO_SDCM_041
          data-read-access:
            access dra_RP_SR_ReqLearnUIDTableToSDCM_ReqLearnUIDTableToSDCM: accessed-variable=RP_SR_ReqLearnUIDTableToSDCM.ReqLearnUIDTableToSDCM
          read-local-variables:
            access rlv_IINVVMLSDCM_ToggleReqLearnUIDTableToSDCM: accessed-variable=IINVVMLSDCM_ToggleReqLearnUIDTableToSDCM
          written-local-variables:
            access wlv_IINVVMLSDCM_ToggleReqLearnUIDTableToSDCM: accessed-variable=IINVVMLSDCM_ToggleReqLearnUIDTableToSDCM
        RUND_INVVMLSDCM_SDCM_STATE_20E
          data-read-access:
            access dra_RP_SR_SDCMCodeAppairRes_SDCMCodeAppairRes: accessed-variable=RP_SR_SDCMCodeAppairRes.SDCMCodeAppairRes
          read-local-variables:
            access rlv_IINVVMLSDCM_ToggleSDCMState: accessed-variable=IINVVMLSDCM_ToggleSDCMState
          written-local-variables:
            access wlv_IINVVMLSDCM_ToggleSDCMState: accessed-variable=IINVVMLSDCM_ToggleSDCMState
        RUNI_INVVMLSDCM
          written-local-variables:
            access wlv_IINVVMLSDCM_ResetBSI: accessed-variable=IINVVMLSDCM_ResetBSI
        RUNS_AuthentResult: can-be-invoked-concurrently=true
          data-receive-point-by-values:
            access drp_PRP_SR_ToggleAuthentBU_ToggleAuthentBU: accessed-variable=PRP_SR_ToggleAuthentBU.ToggleAuthentBU
          data-send-points:
            access dsp_PRP_SR_ToggleAuthentBU_ToggleAuthentBU: accessed-variable=PRP_SR_ToggleAuthentBU.ToggleAuthentBU
          read-local-variables:
            access rlv_IINVVMLSDCM_AuthentData: accessed-variable=IINVVMLSDCM_AuthentData
          sync call sscp_RUNS_AuthentResult_RP_CS_INVIO_BU_Notification_Invio_AuthentResult: operation=RP_CS_INVIO_BU_Notification.Invio_AuthentResult, timeout=0
          written-local-variables:
            access wlv_IINVVMLSDCM_AuthentData: accessed-variable=IINVVMLSDCM_AuthentData
        RUNS_CfgReadResult: can-be-invoked-concurrently=true
          sync call sscp_RUNS_CfgReadResult_RP_CS_INVIO_BU_Notification_Invio_CfgReadResult: operation=RP_CS_INVIO_BU_Notification.Invio_CfgReadResult, timeout=0
        RUNS_CfgWriteResult: can-be-invoked-concurrently=true
          sync call sscp_RUNS_CfgWriteResult_RP_CS_INVIO_BU_Notification_Invio_CfgWriteResult: operation=RP_CS_INVIO_BU_Notification.Invio_CfgWriteResult, timeout=0
        RUNS_Error: can-be-invoked-concurrently=true
          data-receive-point-by-values:
            access drp_PRP_SR_ToggleErrorBU_ToggleErrorBU: accessed-variable=PRP_SR_ToggleErrorBU.ToggleErrorBU
          data-send-points:
            access dsp_PRP_SR_ToggleErrorBU_ToggleErrorBU: accessed-variable=PRP_SR_ToggleErrorBU.ToggleErrorBU
          read-local-variables:
            access rlv_IINVVMLSDCM_CommandCode: accessed-variable=IINVVMLSDCM_CommandCode
            access rlv_IINVVMLSDCM_ErrorCode: accessed-variable=IINVVMLSDCM_ErrorCode
          sync call sscp_RUNS_Error_RP_CS_INVIO_BU_Notification_Invio_Error: operation=RP_CS_INVIO_BU_Notification.Invio_Error, timeout=0
          written-local-variables:
            access wlv_IINVVMLSDCM_CommandCode: accessed-variable=IINVVMLSDCM_CommandCode
            access wlv_IINVVMLSDCM_ErrorCode: accessed-variable=IINVVMLSDCM_ErrorCode
        RUNS_IdentResult: can-be-invoked-concurrently=true
          data-receive-point-by-values:
            access drp_PRP_SR_IdentTrspBU_IdentTrspBU: accessed-variable=PRP_SR_IdentTrspBU.IdentTrspBU
            access drp_PRP_SR_ToggleIdentBU_ToggleIdentBU: accessed-variable=PRP_SR_ToggleIdentBU.ToggleIdentBU
          data-send-points:
            access dsp_PRP_SR_IdentTrspBU_IdentTrspBU: accessed-variable=PRP_SR_IdentTrspBU.IdentTrspBU
            access dsp_PRP_SR_ToggleIdentBU_ToggleIdentBU: accessed-variable=PRP_SR_ToggleIdentBU.ToggleIdentBU
          sync call sscp_RUNS_IdentResult_RP_CS_INVIO_BU_Notification_Invio_IdentResult: operation=RP_CS_INVIO_BU_Notification.Invio_IdentResult, timeout=0
        RUNS_INVIO_AuthentRequest: can-be-invoked-concurrently=true
          sync call sscp_RUNS_INVIO_AuthentRequest_RP_CS_TRP_Command_Authent_Request: operation=RP_CS_TRP_Command.Authent_Request, timeout=0
        RUNS_INVIO_CalculerDataAuthent: can-be-invoked-concurrently=true
          data-receive-point-by-values:
            5 x access:
              drp_RP_SR_CodeVIN_{15..17}_CodeVIN_{15..17}: accessed-variable=RP_SR_CodeVIN_{15..17}.CodeVIN_{15..17}
              drp_RP_SR_CFG_GEN_ISK16_CFG_GEN_ISK16: accessed-variable=RP_SR_CFG_GEN_ISK16.CFG_GEN_ISK16
              drp_RP_SR_CINVCOM_TMCF_AES_CINVCOM_TMCF_AES: accessed-variable=RP_SR_CINVCOM_TMCF_AES.CINVCOM_TMCF_AES
        RUNS_INVIO_CalculerRSK: can-be-invoked-concurrently=true
        RUNS_INVIO_CfgReadRequest: can-be-invoked-concurrently=true
          sync call sscp_RUNS_INVIO_CfgReadRequest_RP_CS_TRP_Command_Cfg_Read_Request: operation=RP_CS_TRP_Command.Cfg_Read_Request, timeout=0
        RUNS_INVIO_CfgWriteRequest: can-be-invoked-concurrently=true
          sync call sscp_RUNS_INVIO_CfgWriteRequest_RP_CS_TRP_Command_Cfg_Write_Request: operation=RP_CS_TRP_Command.Cfg_Write_Request, timeout=0
        RUNS_INVIO_FinAppr: can-be-invoked-concurrently=true
        RUNS_INVIO_GetCIDAndStatus: can-be-invoked-concurrently=true
          data-receive-point-by-values:
            11 x access:
              drp_RP_SR_CFG_IdentPlip_CFG_IdentPlip{1..5}: accessed-variable=RP_SR_CFG_IdentPlip.CFG_IdentPlip{1..5}
              drp_RP_SR_CFG_NumBadge_CFG_NumBadge{1..5}: accessed-variable=RP_SR_CFG_NumBadge.CFG_NumBadge{1..5}
              drp_RP_SR_CFG_TYPE_CLE_CFG_TYPE_CLE: accessed-variable=RP_SR_CFG_TYPE_CLE.CFG_TYPE_CLE
          read-local-variables:
            5 x access:
              rlv_IINVVMLSDCM_Cid{1..5}Status: accessed-variable=IINVVMLSDCM_Cid{1..5}Status
        RUNS_INVIO_IdentRequest: can-be-invoked-concurrently=true
          sync call sscp_RUNS_INVIO_IdentRequest_RP_CS_TRP_Command_Ident_Request: operation=RP_CS_TRP_Command.Ident_Request, timeout=0
        RUNS_INVIO_LocMLEnCours: can-be-invoked-concurrently=true
          data-receive-point-by-values:
            access drp_RP_SR_LocalisationStatus_ExternalLocalisationStatus: accessed-variable=RP_SR_LocalisationStatus.ExternalLocalisationStatus
            access drp_RP_SR_LocalisationStatus_InternalLocalisationStatus: accessed-variable=RP_SR_LocalisationStatus.InternalLocalisationStatus
        RUNS_INVIO_ReadRequest: can-be-invoked-concurrently=true
          sync call sscp_RUNS_INVIO_ReadRequest_RP_CS_TRP_Command_Read_Request: operation=RP_CS_TRP_Command.Read_Request, timeout=0
        RUNS_INVIO_ReceiveSegMsg: can-be-invoked-concurrently=true
          read-local-variables:
            22 x access:
              rlv_IINVVMLSDCM_SizeReceiveSegMsg: accessed-variable=IINVVMLSDCM_SizeReceiveSegMsg
              rlv_IINVVMLSDCM_ToggleReceiveSegMsg: accessed-variable=IINVVMLSDCM_ToggleReceiveSegMsg
              rlv_IINVVMLSDCM_UIdNFC1_{1..4}: accessed-variable=IINVVMLSDCM_UIdNFC1_{1..4}
              rlv_IINVVMLSDCM_UIdNFC2_{1..4}: accessed-variable=IINVVMLSDCM_UIdNFC2_{1..4}
              rlv_IINVVMLSDCM_UIdNFC3_{1..4}: accessed-variable=IINVVMLSDCM_UIdNFC3_{1..4}
              rlv_IINVVMLSDCM_UIdNFC4_{1..4}: accessed-variable=IINVVMLSDCM_UIdNFC4_{1..4}
              rlv_IINVVMLSDCM_UIdNFC5_{1..4}: accessed-variable=IINVVMLSDCM_UIdNFC5_{1..4}
          written-local-variables:
            22 x access:
              wlv_IINVVMLSDCM_SizeReceiveSegMsg: accessed-variable=IINVVMLSDCM_SizeReceiveSegMsg
              wlv_IINVVMLSDCM_ToggleReceiveSegMsg: accessed-variable=IINVVMLSDCM_ToggleReceiveSegMsg
              wlv_IINVVMLSDCM_UIdNFC1_{1..4}: accessed-variable=IINVVMLSDCM_UIdNFC1_{1..4}
              wlv_IINVVMLSDCM_UIdNFC2_{1..4}: accessed-variable=IINVVMLSDCM_UIdNFC2_{1..4}
              wlv_IINVVMLSDCM_UIdNFC3_{1..4}: accessed-variable=IINVVMLSDCM_UIdNFC3_{1..4}
              wlv_IINVVMLSDCM_UIdNFC4_{1..4}: accessed-variable=IINVVMLSDCM_UIdNFC4_{1..4}
              wlv_IINVVMLSDCM_UIdNFC5_{1..4}: accessed-variable=IINVVMLSDCM_UIdNFC5_{1..4}
        RUNS_INVIO_WriteRequest: can-be-invoked-concurrently=true
          sync call sscp_RUNS_INVIO_WriteRequest_RP_CS_TRP_Command_Write_Request: operation=RP_CS_TRP_Command.Write_Request, timeout=0
        RUNS_ReadResult: can-be-invoked-concurrently=true
          sync call sscp_RUNS_ReadResult_RP_CS_INVIO_BU_Notification_Invio_ReadResult: operation=RP_CS_INVIO_BU_Notification.Invio_ReadResult, timeout=0
        RUNS_Routine_AppBadgeBML_RequestResults
          read-local-variables:
            access rlv_IINVVMLSDCM_AppBadgeBMLCauseNok: accessed-variable=IINVVMLSDCM_AppBadgeBMLCauseNok
            access rlv_IINVVMLSDCM_AppBadgeBMLStatus: accessed-variable=IINVVMLSDCM_AppBadgeBMLStatus
        RUNS_Routine_AppBadgeBML_Start
          read-local-variables:
            access rlv_IINVVMLSDCM_AppBadgeBMLStart: accessed-variable=IINVVMLSDCM_AppBadgeBMLStart
          written-local-variables:
            4 x access:
              wlv_IINVVMLSDCM_AppBadgeBMLCauseNok: accessed-variable=IINVVMLSDCM_AppBadgeBMLCauseNok
              wlv_IINVVMLSDCM_AppBadgeBMLCodeADC: accessed-variable=IINVVMLSDCM_AppBadgeBMLCodeADC
              wlv_IINVVMLSDCM_AppBadgeBMLStart: accessed-variable=IINVVMLSDCM_AppBadgeBMLStart
              wlv_IINVVMLSDCM_AppBadgeBMLStatus: accessed-variable=IINVVMLSDCM_AppBadgeBMLStatus
        RUNS_Routine_AppBadgeBML_Stop
          read-local-variables:
            access rlv_IINVVMLSDCM_AppBadgeBMLStop: accessed-variable=IINVVMLSDCM_AppBadgeBMLStop
          written-local-variables:
            4 x access:
              wlv_IINVVMLSDCM_AppBadgeBMLCauseNok: accessed-variable=IINVVMLSDCM_AppBadgeBMLCauseNok
              wlv_IINVVMLSDCM_AppBadgeBMLCodeADC: accessed-variable=IINVVMLSDCM_AppBadgeBMLCodeADC
              wlv_IINVVMLSDCM_AppBadgeBMLStatus: accessed-variable=IINVVMLSDCM_AppBadgeBMLStatus
              wlv_IINVVMLSDCM_AppBadgeBMLStop: accessed-variable=IINVVMLSDCM_AppBadgeBMLStop
        RUNS_Routine_ApprUidNFC_RequestResults
          read-local-variables:
            access rlv_IINVVMLSDCM_ApprUidNFCCauseNok: accessed-variable=IINVVMLSDCM_ApprUidNFCCauseNok
            access rlv_IINVVMLSDCM_ApprUidNFCStatus: accessed-variable=IINVVMLSDCM_ApprUidNFCStatus
        RUNS_Routine_ApprUidNFC_Start
          read-local-variables:
            access rlv_IINVVMLSDCM_ApprUidNFCStart: accessed-variable=IINVVMLSDCM_ApprUidNFCStart
          written-local-variables:
            access wlv_IINVVMLSDCM_ApprUidNFCCauseNok: accessed-variable=IINVVMLSDCM_ApprUidNFCCauseNok
            access wlv_IINVVMLSDCM_ApprUidNFCStart: accessed-variable=IINVVMLSDCM_ApprUidNFCStart
            access wlv_IINVVMLSDCM_ApprUidNFCStatus: accessed-variable=IINVVMLSDCM_ApprUidNFCStatus
        RUNS_Routine_ApprUidNFC_Stop
          read-local-variables:
            access rlv_IINVVMLSDCM_ApprUidNFCStop: accessed-variable=IINVVMLSDCM_ApprUidNFCStop
          written-local-variables:
            access wlv_IINVVMLSDCM_ApprUidNFCCauseNok: accessed-variable=IINVVMLSDCM_ApprUidNFCCauseNok
            access wlv_IINVVMLSDCM_ApprUidNFCStatus: accessed-variable=IINVVMLSDCM_ApprUidNFCStatus
            access wlv_IINVVMLSDCM_ApprUidNFCStop: accessed-variable=IINVVMLSDCM_ApprUidNFCStop
        RUNS_WriteResult: can-be-invoked-concurrently=true
          sync call sscp_RUNS_WriteResult_RP_CS_INVIO_BU_Notification_Invio_WriteResult: operation=RP_CS_INVIO_BU_Notification.Invio_WriteResult, timeout=0
package /RootP_Implementation
  swc implementation Implementatation_ASWC_M137: programming-language=C, sw-version=1.0.0, vendor-id=1, behavior=IB_ASWC_M137
    code-descriptors:
      code SRC: artifact-descriptors=autosar-engineering-object={short-label=EngObject, category=SWSRC}
    resource consumption Resources
      memory section CODE: sw-addrmethod=CODE_ASWC_M137
  sw addr method CODE_ASWC_M137: memory-allocation-keyword-policy=ADDR-METHOD-SHORT-NAME-AND-ALIGNMENT, section-type=CODE
